VERSION "dbc-export 1 2025.20.8"

NS_ :

BS_:

BU_: APP APS DAS EPAS3S ESP GTW IBST PARK RADC RCM TPMS USM

BO_ 1045 APP_backupDashCamStatus: 1 APP
 SG_ APP_backupDashCamFeedGood : 0|1@1+ (1,0) [0|1] "" Vector__XXX
 SG_ APP_backupDashCamFrameRate : 1|7@1+ (1,0) [0|127] "" Vector__XXX

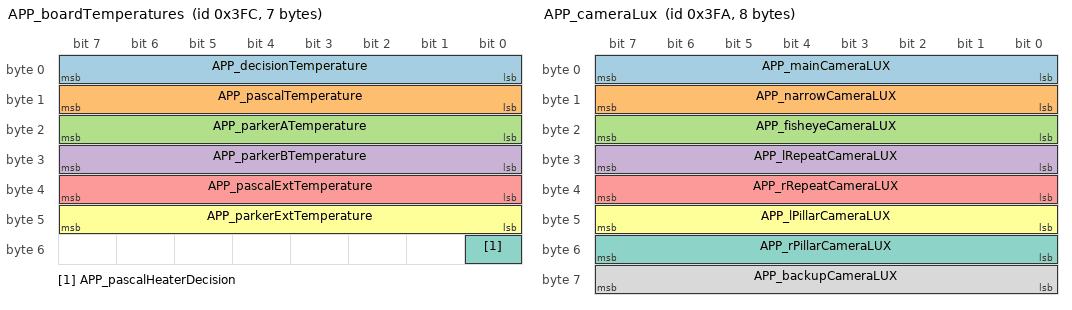
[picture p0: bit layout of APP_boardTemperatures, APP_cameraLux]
BO_ 1020 APP_boardTemperatures: 7 APP
 SG_ APP_decisionTemperature : 0|8@1+ (1,-128) [-128|127] "C" Vector__XXX
 SG_ APP_pascalTemperature : 8|8@1+ (1,-128) [-128|127] "C" Vector__XXX
 SG_ APP_parkerATemperature : 16|8@1+ (1,-128) [-128|127] "C" Vector__XXX
 SG_ APP_parkerBTemperature : 24|8@1+ (1,-128) [-128|127] "C" Vector__XXX
 SG_ APP_pascalExtTemperature : 32|8@1+ (1,-128) [-128|127] "C" Vector__XXX
 SG_ APP_parkerExtTemperature : 40|8@1+ (1,-128) [-128|127] "C" Vector__XXX
 SG_ APP_pascalHeaterDecision : 48|1@1+ (1,0) [0|1] "" Vector__XXX

BO_ 1018 APP_cameraLux: 8 APP
 SG_ APP_mainCameraLUX : 0|8@1+ (0.5,0) [0|127] "lux^0.5" Vector__XXX
 SG_ APP_narrowCameraLUX : 8|8@1+ (0.5,0) [0|127] "lux^0.5" Vector__XXX
 SG_ APP_fisheyeCameraLUX : 16|8@1+ (0.5,0) [0|127] "lux^0.5" Vector__XXX
 SG_ APP_lRepeatCameraLUX : 24|8@1+ (0.5,0) [0|127] "lux^0.5" Vector__XXX
 SG_ APP_rRepeatCameraLUX : 32|8@1+ (0.5,0) [0|127] "lux^0.5" Vector__XXX
 SG_ APP_lPillarCameraLUX : 40|8@1+ (0.5,0) [0|127] "lux^0.5" Vector__XXX
 SG_ APP_rPillarCameraLUX : 48|8@1+ (0.5,0) [0|127] "lux^0.5" Vector__XXX
 SG_ APP_backupCameraLUX : 56|8@1+ (0.5,0) [0|127] "lux^0.5" Vector__XXX

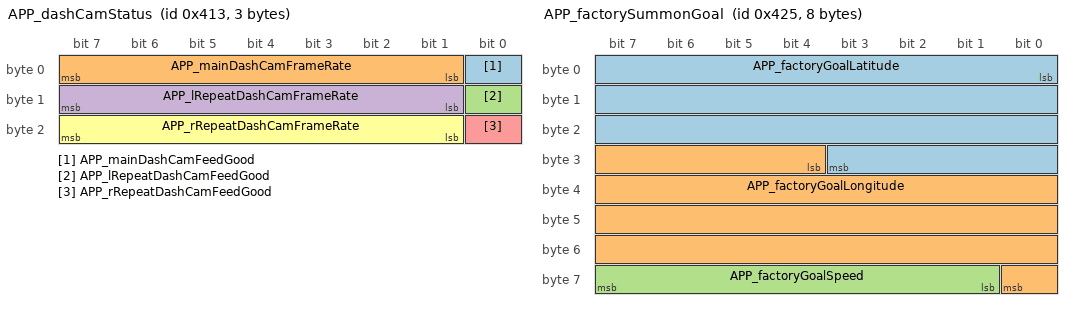
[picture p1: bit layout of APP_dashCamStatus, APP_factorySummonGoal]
BO_ 1043 APP_dashCamStatus: 3 APP
 SG_ APP_mainDashCamFeedGood : 0|1@1+ (1,0) [0|1] "" Vector__XXX
 SG_ APP_mainDashCamFrameRate : 1|7@1+ (1,0) [0|127] "" Vector__XXX
 SG_ APP_lRepeatDashCamFeedGood : 8|1@1+ (1,0) [0|1] "" Vector__XXX
 SG_ APP_lRepeatDashCamFrameRate : 9|7@1+ (1,0) [0|127] "" Vector__XXX
 SG_ APP_rRepeatDashCamFeedGood : 16|1@1+ (1,0) [0|1] "" Vector__XXX
 SG_ APP_rRepeatDashCamFrameRate : 17|7@1+ (1,0) [0|127] "" Vector__XXX

BO_ 1061 APP_factorySummonGoal: 8 APP
 SG_ APP_factoryGoalLatitude : 0|28@1- (1.0e-06,0) [-134.217728|134.217727] "deg" Vector__XXX
 SG_ APP_factoryGoalLongitude : 28|29@1- (1.0e-06,0) [-268.435456|268.435454] "deg" Vector__XXX
 SG_ APP_factoryGoalSpeed : 57|7@1+ (1,0) [0|100] "mph" Vector__XXX

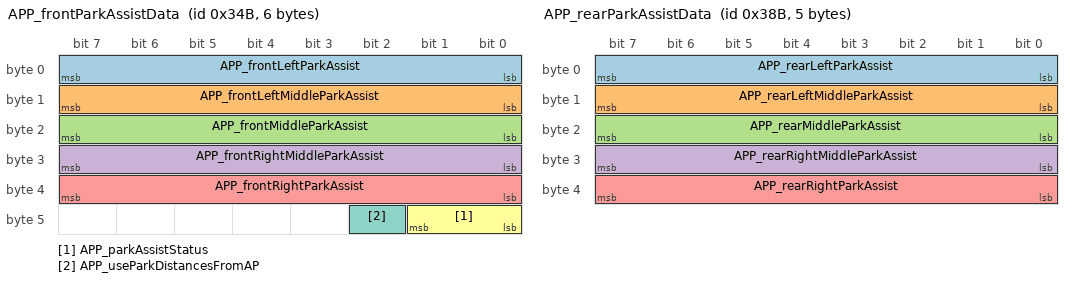
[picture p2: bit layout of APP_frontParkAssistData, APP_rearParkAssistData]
BO_ 843 APP_frontParkAssistData: 6 APP
 SG_ APP_frontLeftParkAssist : 0|8@1+ (1,0) [0|254] "cm" Vector__XXX
 SG_ APP_frontLeftMiddleParkAssist : 8|8@1+ (1,0) [0|254] "cm" Vector__XXX
 SG_ APP_frontMiddleParkAssist : 16|8@1+ (1,0) [0|254] "cm" Vector__XXX
 SG_ APP_frontRightMiddleParkAssist : 24|8@1+ (1,0) [0|254] "cm" Vector__XXX
 SG_ APP_frontRightParkAssist : 32|8@1+ (1,0) [0|254] "cm" Vector__XXX
 SG_ APP_parkAssistStatus : 40|2@1+ (1,0) [0|2] "" Vector__XXX
 SG_ APP_useParkDistancesFromAP : 42|1@1+ (1,0) [0|1] "" Vector__XXX

BO_ 1353 APP_info: 8 APP
 SG_ APP_infoIndex M : 0|8@1+ (1,0) [0|255] "" Vector__XXX
 SG_ APP_buildType m0 : 8|8@1+ (1,0) [0|255] "" Vector__XXX

BO_ 907 APP_rearParkAssistData: 5 APP
 SG_ APP_rearLeftParkAssist : 0|8@1+ (1,0) [0|254] "cm" Vector__XXX
 SG_ APP_rearLeftMiddleParkAssist : 8|8@1+ (1,0) [0|254] "cm" Vector__XXX
 SG_ APP_rearMiddleParkAssist : 16|8@1+ (1,0) [0|254] "cm" Vector__XXX
 SG_ APP_rearRightMiddleParkAssist : 24|8@1+ (1,0) [0|254] "cm" Vector__XXX
 SG_ APP_rearRightParkAssist : 32|8@1+ (1,0) [0|254] "cm" Vector__XXX

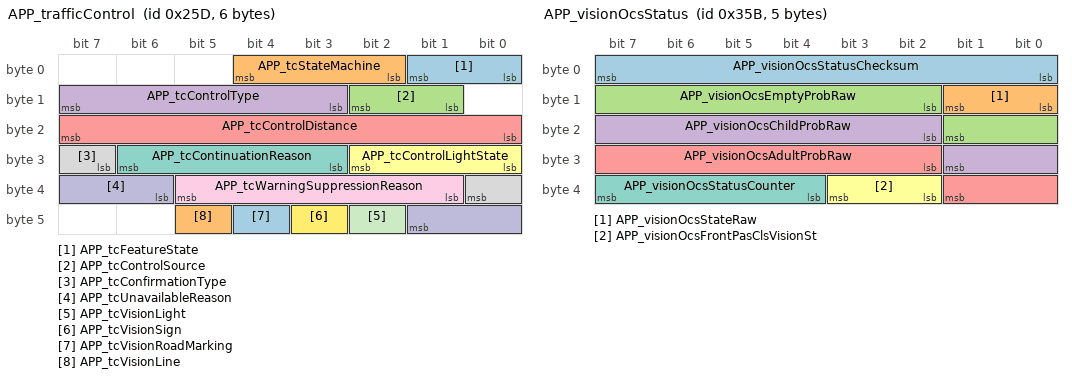
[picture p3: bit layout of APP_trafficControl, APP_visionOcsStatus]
BO_ 605 APP_trafficControl: 6 APP
 SG_ APP_tcFeatureState : 0|2@1+ (1,0) [0|3] "" Vector__XXX
 SG_ APP_tcStateMachine : 2|3@1+ (1,0) [0|7] "" Vector__XXX
 SG_ APP_tcControlSource : 9|2@1+ (1,0) [0|3] "" Vector__XXX
 SG_ APP_tcControlType : 11|5@1+ (1,0) [0|31] "" Vector__XXX
 SG_ APP_tcControlDistance : 16|8@1+ (1,0) [0|254] "m" Vector__XXX
 SG_ APP_tcControlLightState : 24|3@1+ (1,0) [0|7] "" Vector__XXX
 SG_ APP_tcContinuationReason : 27|4@1+ (1,0) [0|15] "" Vector__XXX
 SG_ APP_tcConfirmationType : 31|2@1+ (1,0) [0|3] "" Vector__XXX
 SG_ APP_tcWarningSuppressionReason : 33|5@1+ (1,0) [0|31] "" Vector__XXX
 SG_ APP_tcUnavailableReason : 38|4@1+ (1,0) [0|15] "" Vector__XXX
 SG_ APP_tcVisionLight : 42|1@1+ (1,0) [0|1] "" Vector__XXX
 SG_ APP_tcVisionSign : 43|1@1+ (1,0) [0|1] "" Vector__XXX
 SG_ APP_tcVisionRoadMarking : 44|1@1+ (1,0) [0|1] "" Vector__XXX
 SG_ APP_tcVisionLine : 45|1@1+ (1,0) [0|1] "" Vector__XXX

BO_ 859 APP_visionOcsStatus: 5 APP
 SG_ APP_visionOcsStatusChecksum : 0|8@1+ (1,0) [0|255] "" Vector__XXX
 SG_ APP_visionOcsStateRaw : 8|2@1+ (1,0) [0|3] "" Vector__XXX
 SG_ APP_visionOcsEmptyProbRaw : 10|8@1+ (0.004,0) [0|1.016] "points" Vector__XXX
 SG_ APP_visionOcsChildProbRaw : 18|8@1+ (0.004,0) [0|1.016] "points" Vector__XXX
 SG_ APP_visionOcsAdultProbRaw : 26|8@1+ (0.004,0) [0|1.016] "points" Vector__XXX
 SG_ APP_visionOcsFrontPasClsVisionSt : 34|2@1+ (1,0) [0|3] "" Vector__XXX
 SG_ APP_visionOcsStatusCounter : 36|4@1+ (1,0) [0|15] "" Vector__XXX

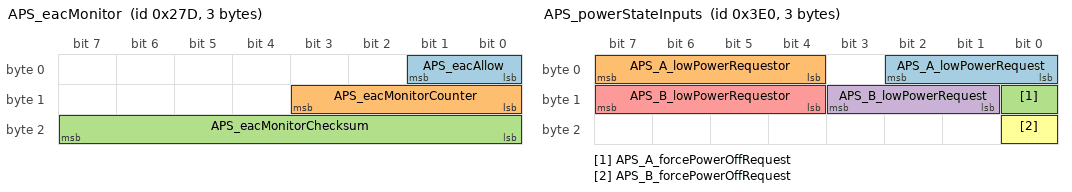
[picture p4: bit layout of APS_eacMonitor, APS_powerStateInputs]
BO_ 637 APS_eacMonitor: 3 APS
 SG_ APS_eacAllow : 0|2@1+ (1,0) [0|2] "" Vector__XXX
 SG_ APS_eacMonitorCounter : 8|4@1+ (1,0) [0|15] "" Vector__XXX
 SG_ APS_eacMonitorChecksum : 16|8@1+ (1,0) [0|255] "" Vector__XXX

BO_ 992 APS_powerStateInputs: 3 APS
 SG_ APS_A_lowPowerRequest : 0|3@1+ (1,0) [0|7] "" Vector__XXX
 SG_ APS_A_lowPowerRequestor : 4|4@1+ (1,0) [0|15] "" Vector__XXX
 SG_ APS_A_forcePowerOffRequest : 8|1@1+ (1,0) [0|1] "" Vector__XXX
 SG_ APS_B_lowPowerRequest : 9|3@1+ (1,0) [0|7] "" Vector__XXX
 SG_ APS_B_lowPowerRequestor : 12|4@1+ (1,0) [0|15] "" Vector__XXX
 SG_ APS_B_forcePowerOffRequest : 16|1@1+ (1,0) [0|1] "" Vector__XXX

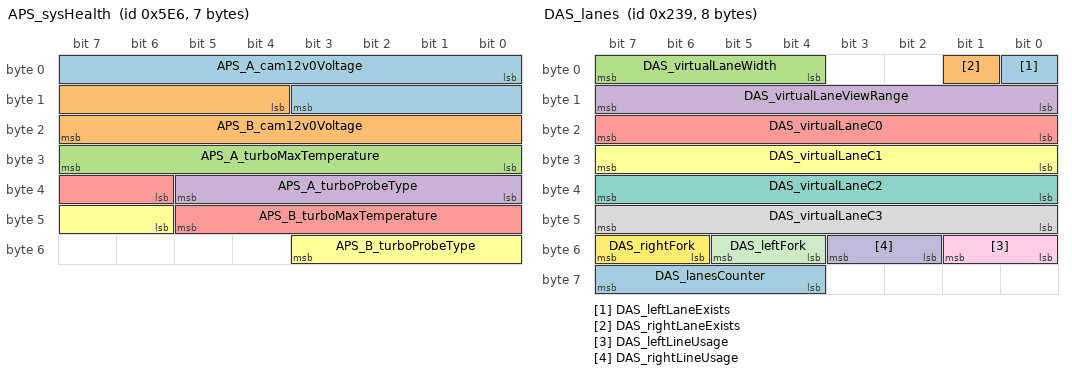
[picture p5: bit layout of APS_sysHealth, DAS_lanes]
BO_ 1510 APS_sysHealth: 7 APS
 SG_ APS_A_cam12v0Voltage : 0|12@1+ (0.0048,0) [0|19.44] "V" Vector__XXX
 SG_ APS_B_cam12v0Voltage : 12|12@1+ (0.0048,0) [0|19.44] "V" Vector__XXX
 SG_ APS_A_turboMaxTemperature : 24|8@1- (1,0) [-128|127] "degC" Vector__XXX
 SG_ APS_A_turboProbeType : 32|6@1+ (1,0) [0|62] "" Vector__XXX
 SG_ APS_B_turboMaxTemperature : 38|8@1- (1,0) [-128|127] "degC" Vector__XXX
 SG_ APS_B_turboProbeType : 46|6@1+ (1,0) [0|62] "" Vector__XXX

BO_ 1497 DAS_carLog: 8 DAS
 SG_ DAS_carLogMultiplexer M : 0|4@1+ (1,0) [0|15] "" Vector__XXX
 SG_ DAS_radarTarget5_dx m1 : 4|12@1+ (0.0625,0) [0|255.9375] "m" Vector__XXX
 SG_ DAS_radarTarget1_dx m1 : 24|12@1+ (0.0625,0) [0|255.9375] "m" Vector__XXX
 SG_ DAS_radarTarget1_VxRel m1 : 36|8@1+ (0.2,-25.6) [-25.6|25.4] "m/s" Vector__XXX
 SG_ DAS_mobileyeVehAebFlag m2 : 4|1@1+ (1,0) [0|1] "" Vector__XXX
 SG_ DAS_mobileyePedAebFlag m2 : 5|1@1+ (1,0) [0|1] "" Vector__XXX
 SG_ DAS_mobileyeIPSOapproved m2 : 6|1@1+ (1,0) [0|1] "" Vector__XXX
 SG_ DAS_fcmSteeringOverride m2 : 7|1@1+ (1,0) [0|1] "" Vector__XXX
 SG_ DAS_fcmCollisionStage3Checks m2 : 8|8@1+ (1,0) [0|255] "" Vector__XXX
 SG_ DAS_fcmThreatAssesmentMode m2 : 16|3@1+ (1,0) [0|7] "" Vector__XXX
 SG_ DAS_constructionArea m2 : 19|2@1+ (1,0) [0|3] "" Vector__XXX
 SG_ DAS_restrictionLowSpeedTraffic m2 : 21|1@1+ (1,0) [0|1] "" Vector__XXX
 SG_ DAS_associated_rad_object m2 : 22|2@1+ (1,0) [0|3] "" Vector__XXX
 SG_ DAS_LC_handsOnReason m2 : 24|6@1+ (1,0) [0|63] "" Vector__XXX
 SG_ DAS_ACC_camStatus m2 : 30|2@1+ (1,0) [0|3] "" Vector__XXX
 SG_ DAS_aeb_not_activating_reason m2 : 32|5@1+ (1,0) [0|31] "" Vector__XXX
 SG_ DAS_handsOnDetected m2 : 38|2@1+ (1,0) [1|3] "" Vector__XXX
 SG_ DAS_driveOnNavUnavailableReason m2 : 40|5@1+ (1,0) [0|31] "" Vector__XXX
 SG_ DAS_accUnavailableReason m2 : 46|7@1+ (1,0) [0|127] "" Vector__XXX
 SG_ DAS_pmmNotActivatingReason m2 : 53|5@1+ (1,0) [0|31] "" Vector__XXX
 SG_ DAS_desiredTarget_dx m3 : 16|8@1+ (0.5,0) [0|127] "m" Vector__XXX
 SG_ DAS_radarTarget2_dx m3 : 24|12@1+ (0.0625,0) [0|255.9375] "m" Vector__XXX
 SG_ DAS_radarTarget3_dx m3 : 36|12@1+ (0.0625,0) [0|255.9375] "m" Vector__XXX
 SG_ DAS_radarTarget4_dx m3 : 48|12@1+ (0.0625,0) [0|255.9375] "m" Vector__XXX
 SG_ DAS_closestInLaneTargetDx m4 : 4|12@1+ (0.0625,0) [0|255.9375] "m" Vector__XXX
 SG_ DAS_secondInLaneTargetDx m4 : 16|12@1+ (0.0625,0) [0|255.9375] "m" Vector__XXX
 SG_ DAS_closestLeftLaneTargetDx m4 : 28|12@1+ (0.0625,0) [0|255.9375] "m" Vector__XXX
 SG_ DAS_closestRightLaneTargetDx m4 : 40|12@1+ (0.0625,0) [0|255.9375] "m" Vector__XXX
 SG_ DAS_closestInLaneTargetVxRel m4 : 52|10@1+ (0.1,-51.1) [-51.1|51.2] "m/s" Vector__XXX

BO_ 1337 DAS_info: 8 DAS
 SG_ DAS_infoIndex M : 0|8@1+ (1,0) [0|255] "" Vector__XXX
 SG_ DAS_infoBuildType m10 : 8|8@1+ (1,0) [0|255] "" Vector__XXX
 SG_ DAS_infoBuildConfigID m10 : 16|16@1+ (1,0) [0|65535] "" Vector__XXX
 SG_ DAS_infoHardwareID m10 : 32|16@1+ (1,0) [0|65535] "" Vector__XXX
 SG_ DAS_infoComponentID m10 : 48|16@1+ (1,0) [0|65535] "" Vector__XXX
 SG_ DAS_infoPcbaID m11 : 16|8@1+ (1,0) [0|255] "" Vector__XXX
 SG_ DAS_infoAssemblyID m11 : 24|8@1+ (1,0) [0|255] "" Vector__XXX
 SG_ DAS_infoUsageID m11 : 32|16@1+ (1,0) [0|65535] "" Vector__XXX
 SG_ DAS_infoSubUsageID m11 : 48|16@1+ (1,0) [0|65535] "" Vector__XXX
 SG_ DAS_infoApplicationCRC m13 : 32|32@1+ (1,0) [0|4294967295] "" Vector__XXX
 SG_ DAS_infoAppGitHashBytes m17 : 8|56@1+ (1,0) [0|7.20575940379e+16] "" Vector__XXX
 SG_ DAS_infoBootGitHashBytes m18 : 8|56@1+ (1,0) [0|7.20575940379e+16] "" Vector__XXX

BO_ 569 DAS_lanes: 8 DAS
 SG_ DAS_leftLaneExists : 0|1@1+ (1,0) [0|1] "" Vector__XXX
 SG_ DAS_rightLaneExists : 1|1@1+ (1,0) [0|1] "" Vector__XXX
 SG_ DAS_virtualLaneWidth : 4|4@1+ (0.3125,2) [2|6.6875] "m" Vector__XXX
 SG_ DAS_virtualLaneViewRange : 8|8@1+ (1,0) [0|160] "m" Vector__XXX
 SG_ DAS_virtualLaneC0 : 16|8@1+ (0.035,-3.5) [-3.5|3.5] "m" Vector__XXX
 SG_ DAS_virtualLaneC1 : 24|8@1+ (0.0016,-0.2) [-0.2|0.2] "rad" Vector__XXX
 SG_ DAS_virtualLaneC2 : 32|8@1+ (2.0e-05,-0.0025) [-0.0025|0.0025] "m-1" Vector__XXX
 SG_ DAS_virtualLaneC3 : 40|8@1+ (2.4e-07,-3.0e-05) [-3.0e-05|3.0e-05] "m-2" Vector__XXX
 SG_ DAS_leftLineUsage : 48|2@1+ (1,0) [0|3] "" Vector__XXX
 SG_ DAS_rightLineUsage : 50|2@1+ (1,0) [0|3] "" Vector__XXX
 SG_ DAS_leftFork : 52|2@1+ (1,0) [0|3] "" Vector__XXX
 SG_ DAS_rightFork : 54|2@1+ (1,0) [0|3] "" Vector__XXX
 SG_ DAS_lanesCounter : 60|4@1+ (1,0) [0|15] "" Vector__XXX

BO_ 921 DAS_status: 8 DAS
 SG_ DAS_autopilotState : 0|4@1+ (1,0) [0|14] "" Vector__XXX
 SG_ DAS_blindSpotRearLeft : 4|2@1+ (1,0) [0|2] "" Vector__XXX
 SG_ DAS_blindSpotRearRight : 6|2@1+ (1,0) [0|2] "" Vector__XXX
 SG_ DAS_fusedSpeedLimit : 8|5@1+ (5,0) [5|150] "kph/mph" Vector__XXX
 SG_ DAS_suppressSpeedWarning : 13|1@1+ (1,0) [0|1] "" Vector__XXX
 SG_ DAS_summonObstacle : 14|1@1+ (1,0) [0|1] "" Vector__XXX
 SG_ DAS_summonClearedGate : 15|1@1+ (1,0) [0|1] "" Vector__XXX
 SG_ DAS_visionOnlySpeedLimit : 16|5@1+ (5,0) [5|150] "kph/mph" Vector__XXX
 SG_ DAS_heaterState : 21|1@1+ (1,0) [0|1] "" Vector__XXX
 SG_ DAS_forwardCollisionWarning : 22|2@1+ (1,0) [0|2] "" Vector__XXX
 SG_ DAS_autoparkReady : 24|1@1+ (1,0) [0|1] "" Vector__XXX
 SG_ DAS_autoParked : 25|1@1+ (1,0) [0|1] "" Vector__XXX
 SG_ DAS_autoparkActive : 26|1@1+ (1,0) [0|1] "" Vector__XXX
 SG_ DAS_summonFwdLeashReached : 27|1@1+ (1,0) [0|1] "" Vector__XXX
 SG_ DAS_summonRvsLeashReached : 28|1@1+ (1,0) [0|1] "" Vector__XXX
 SG_ DAS_lssState : 29|3@1+ (1,0) [0|7] "" Vector__XXX
 SG_ DAS_sideCollisionAvoid : 32|2@1+ (1,0) [0|2] "" Vector__XXX
 SG_ DAS_sideCollisionWarning : 34|2@1+ (1,0) [0|3] "" Vector__XXX
 SG_ DAS_sideCollisionInhibit : 36|1@1+ (1,0) [0|1] "" Vector__XXX
 SG_ DAS_laneDepartureWarning : 37|3@1+ (1,0) [0|7] "" Vector__XXX
 SG_ DAS_fleetSpeedState : 40|2@1+ (1,0) [0|3] "" Vector__XXX
 SG_ DAS_autopilotHandsOnState : 42|4@1+ (1,0) [0|14] "" Vector__XXX
 SG_ DAS_autoLaneChangeState : 46|5@1+ (1,0) [0|30] "" Vector__XXX
 SG_ DAS_summonAvailable : 51|1@1+ (1,0) [0|1] "" Vector__XXX
 SG_ DAS_statusCounter : 52|4@1+ (1,0) [0|15] "" Vector__XXX
 SG_ DAS_statusChecksum : 56|8@1+ (1,0) [0|255] "" Vector__XXX

BO_ 905 DAS_status2: 8 DAS
 SG_ DAS_accSpeedLimit : 0|9@1+ (0.4,0) [0|200] "mph" Vector__XXX
 SG_ DAS_versionIdentifier : 9|1@1+ (1,0) [0|1] "" Vector__XXX
 SG_ DAS_pmmObstacleSeverity : 10|3@1+ (1,0) [0|6] "" Vector__XXX
 SG_ DAS_pmmLoggingRequest : 13|1@1+ (1,0) [0|1] "" Vector__XXX
 SG_ DAS_activationFailureStatus : 14|2@1+ (1,0) [0|3] "" Vector__XXX
 SG_ DAS_pmmUltrasonicsFaultReason : 16|3@1+ (1,0) [0|7] "" Vector__XXX
 SG_ DAS_pmmRadarFaultReason : 19|2@1+ (1,0) [0|3] "" Vector__XXX
 SG_ DAS_pmmSysFaultReason : 21|3@1+ (1,0) [0|7] "" Vector__XXX
 SG_ DAS_pmmCameraFaultReason : 24|2@1+ (1,0) [0|3] "" Vector__XXX
 SG_ DAS_ACC_report : 26|5@1+ (1,0) [0|31] "" Vector__XXX
 SG_ DAS_relaxCruiseLimits : 31|1@1+ (1,0) [0|1] "" Vector__XXX
 SG_ DAS_csaState : 32|2@1+ (1,0) [0|3] "" Vector__XXX
 SG_ DAS_radarTelemetry : 34|2@1+ (1,0) [0|3] "" Vector__XXX
 SG_ DAS_robState : 36|2@1+ (1,0) [0|3] "" Vector__XXX
 SG_ DAS_driverInteractionLevel : 38|2@1+ (1,0) [0|3] "" Vector__XXX
 SG_ DAS_ppOffsetDesiredRamp : 40|8@1+ (0.01,-1.28) [-1.28|1.27] "m" Vector__XXX
 SG_ DAS_longCollisionWarning : 48|4@1+ (1,0) [0|14] "" Vector__XXX
 SG_ DAS_status2Counter : 52|4@1+ (1,0) [0|15] "" Vector__XXX
 SG_ DAS_status2Checksum : 56|8@1+ (1,0) [0|255] "" Vector__XXX

BO_ 586 DAS_visualDebug: 8 DAS
 SG_ DAS_autosteerVehiclesUsage : 4|2@1+ (1,0) [0|3] "" Vector__XXX
 SG_ DAS_autosteerHPPUsage : 6|2@1+ (1,0) [0|3] "" Vector__XXX
 SG_ DAS_autosteerNavigationUsage : 8|2@1+ (1,0) [0|3] "" Vector__XXX
 SG_ DAS_autosteerModelUsage : 10|2@1+ (1,0) [0|3] "" Vector__XXX
 SG_ DAS_autosteerBottsDotsUsage : 12|2@1+ (1,0) [0|3] "" Vector__XXX
 SG_ DAS_offsetSide : 14|2@1+ (1,0) [0|3] "" Vector__XXX
 SG_ DAS_roadSurfaceType : 16|2@1+ (1,0) [1|3] "" Vector__XXX
 SG_ DAS_autosteerHealthAnomalyLevel : 18|3@1+ (1,0) [0|7] "" Vector__XXX
 SG_ DAS_autosteerHealthState : 21|3@1+ (1,0) [0|7] "" Vector__XXX
 SG_ DAS_lastLinePreferenceReason : 24|4@1+ (1,0) [0|15] "" Vector__XXX
 SG_ DAS_plannerState : 28|4@1+ (1,0) [0|15] "" Vector__XXX
 SG_ DAS_lastAutosteerAbortReason : 32|6@1+ (1,0) [0|63] "" Vector__XXX
 SG_ DAS_devAppInterfaceEnabled : 38|1@1+ (1,0) [0|1] "" Vector__XXX
 SG_ DAS_navAvailable : 39|1@1+ (1,0) [0|1] "" Vector__XXX
 SG_ DAS_navDistance : 40|8@1+ (100,0) [0|25500] "km" Vector__XXX
 SG_ DAS_accSmartSpeedActive : 48|1@1+ (1,0) [0|1] "" Vector__XXX
 SG_ DAS_accSmartSpeedState : 49|3@1+ (1,0) [0|6] "" Vector__XXX
 SG_ DAS_ulcInProgress : 52|1@1+ (1,0) [0|1] "" Vector__XXX
 SG_ DAS_trafficAwareSetSpeedInUse : 53|1@1+ (1,0) [0|1] "" Vector__XXX
 SG_ DAS_isaSystemState : 54|2@1+ (1,0) [0|3] "" Vector__XXX
 SG_ DAS_behaviorType : 56|2@1+ (1,0) [0|3] "" Vector__XXX
 SG_ DAS_ulcType : 58|2@1+ (1,0) [0|3] "" Vector__XXX
 SG_ DAS_rearVehDetectedThisCycle : 60|1@1+ (1,0) [0|1] "" Vector__XXX
 SG_ DAS_rearLeftVehDetectedCurrent : 61|1@1+ (1,0) [0|1] "" Vector__XXX
 SG_ DAS_rearRightVehDetectedTrip : 62|1@1+ (1,0) [0|1] "" Vector__XXX
 SG_ DAS_rearLeftVehDetectedTrip : 63|1@1+ (1,0) [0|1] "" Vector__XXX

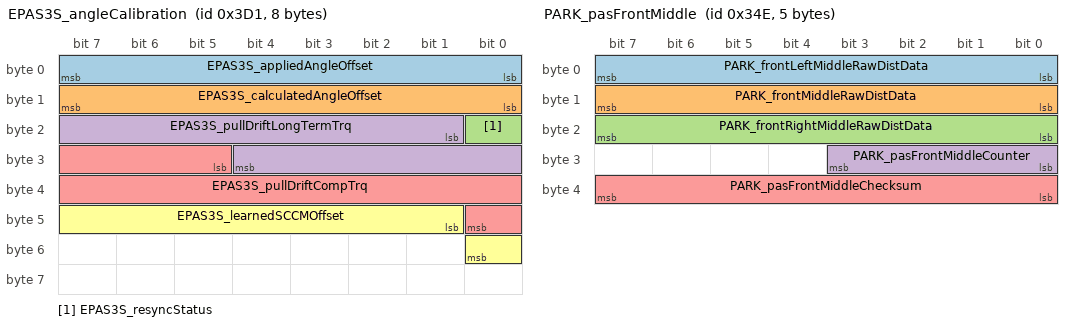
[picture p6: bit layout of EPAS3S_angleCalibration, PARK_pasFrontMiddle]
BO_ 977 EPAS3S_angleCalibration: 8 EPAS3S
 SG_ EPAS3S_appliedAngleOffset : 0|8@1+ (0.1,-12.8) [-12.8|12.7] "deg" Vector__XXX
 SG_ EPAS3S_calculatedAngleOffset : 8|8@1+ (0.1,-12.8) [-12.8|12.7] "deg" Vector__XXX
 SG_ EPAS3S_resyncStatus : 16|1@1+ (1,0) [0|1] "" Vector__XXX
 SG_ EPAS3S_pullDriftLongTermTrq : 17|12@1+ (0.01,-10) [-10|10] "Nm" Vector__XXX
 SG_ EPAS3S_pullDriftCompTrq : 29|12@1+ (0.01,-10) [-10|10] "Nm" Vector__XXX
 SG_ EPAS3S_learnedSCCMOffset : 41|8@1+ (0.1,-12.8) [-12.8|12.7] "deg" Vector__XXX

BO_ 785 EPAS3S_info: 8 EPAS3S
 SG_ EPAS3S_infoIndex M : 0|8@1+ (1,0) [0|255] "" Vector__XXX
 SG_ EPAS3S_infoBuildType m10 : 8|8@1+ (1,0) [0|255] "" Vector__XXX
 SG_ EPAS3S_infoComponentID m10 : 48|16@1+ (1,0) [0|65535] "" Vector__XXX
 SG_ EPAS3S_infoPcbaID m11 : 16|8@1+ (1,0) [0|255] "" Vector__XXX
 SG_ EPAS3S_infoAssemblyID m11 : 24|8@1+ (1,0) [0|255] "" Vector__XXX
 SG_ EPAS3S_infoUsageID m11 : 32|16@1+ (1,0) [0|65535] "" Vector__XXX
 SG_ EPAS3S_infoApplicationCRC m13 : 32|32@1+ (1,0) [0|4294967295] "" Vector__XXX
 SG_ EPAS3S_infoBootUdsProtoVersion m20 : 8|8@1+ (1,0) [0|255] "" Vector__XXX
 SG_ EPAS3S_infoBootloaderCRC m20 : 32|32@1+ (1,0) [0|4294967295] "" Vector__XXX
 SG_ EPAS3S_infoSubcomponent2 m23 : 32|32@1+ (1,0) [0|4294967295] "" Vector__XXX

BO_ 805 ESP_info: 8 ESP
 SG_ ESP_infoIndex M : 0|8@1+ (1,0) [0|255] "" Vector__XXX
 SG_ ESP_infoBuildType m10 : 8|8@1+ (1,0) [0|255] "" Vector__XXX
 SG_ ESP_infoComponentID m10 : 48|16@1+ (1,0) [0|65535] "" Vector__XXX
 SG_ ESP_infoPcbaID m11 : 16|8@1+ (1,0) [0|255] "" Vector__XXX
 SG_ ESP_infoAssemblyID m11 : 24|8@1+ (1,0) [0|255] "" Vector__XXX
 SG_ ESP_infoUsageID m11 : 32|16@1+ (1,0) [0|65535] "" Vector__XXX
 SG_ ESP_infoSubUsageID m11 : 48|16@1+ (1,0) [0|65535] "" Vector__XXX
 SG_ ESP_infoApplicationCRC m13 : 39|32@0+ (1,0) [0|4294967295] "" Vector__XXX
 SG_ ESP_infoVehicleVariant m16 : 16|8@1+ (1,0) [0|255] "" Vector__XXX
 SG_ ESP_infoSubcomponent1 m16 : 32|32@1+ (1,0) [0|4294967295] "" Vector__XXX
 SG_ ESP_infoBootUdsProtoVersion m20 : 8|8@1+ (1,0) [0|255] "" Vector__XXX
 SG_ ESP_infoBootloaderCRC m20 : 32|32@1+ (1,0) [0|4294967295] "" Vector__XXX
 SG_ ESP_infoVariantCRC m22 : 39|32@0+ (1,0) [0|4294967295] "" Vector__XXX

BO_ 813 IBST_info: 8 IBST
 SG_ IBST_infoIndex M : 0|8@1+ (1,0) [0|255] "" Vector__XXX
 SG_ IBST_infoBuildType m10 : 8|8@1+ (1,0) [0|255] "" Vector__XXX
 SG_ IBST_infoComponentID m10 : 55|16@0+ (1,0) [0|65535] "" Vector__XXX
 SG_ IBST_infoPcbaID m11 : 16|8@1+ (1,0) [0|255] "" Vector__XXX
 SG_ IBST_infoAssemblyID m11 : 24|8@1+ (1,0) [0|255] "" Vector__XXX
 SG_ IBST_infoUsageID m11 : 32|16@1+ (1,0) [0|65535] "" Vector__XXX
 SG_ IBST_infoSubUsageID m11 : 48|16@1+ (1,0) [0|65535] "" Vector__XXX
 SG_ IBST_infoApplicationCRC m13 : 32|32@1+ (1,0) [0|4294967295] "" Vector__XXX
 SG_ IBST_infoBootUdsProtoVersion m20 : 8|8@1+ (1,0) [0|255] "" Vector__XXX
 SG_ IBST_infoBootloaderCRC m20 : 32|32@1+ (1,0) [0|4294967295] "" Vector__XXX
 SG_ IBST_infoVariantCRC m22 : 32|32@1+ (1,0) [0|4294967295] "" Vector__XXX

BO_ 806 PARK_info: 8 PARK
 SG_ PARK_infoIndex M : 0|8@1+ (1,0) [0|255] "" Vector__XXX
 SG_ PARK_infoBuildType m10 : 8|8@1+ (1,0) [0|255] "" Vector__XXX
 SG_ PARK_infoComponentID m10 : 48|16@1+ (1,0) [0|65535] "" Vector__XXX
 SG_ PARK_infoPcbaID m11 : 16|8@1+ (1,0) [0|255] "" Vector__XXX
 SG_ PARK_infoAssemblyID m11 : 24|8@1+ (1,0) [0|255] "" Vector__XXX
 SG_ PARK_infoUsageID m11 : 32|16@1+ (1,0) [0|65535] "" Vector__XXX
 SG_ PARK_infoApplicationCRC m13 : 32|32@1+ (1,0) [0|4294967295] "" Vector__XXX
 SG_ PARK_infoBootUdsProtoVersion m20 : 8|8@1+ (1,0) [0|255] "" Vector__XXX
 SG_ PARK_infoBootloaderCRC m20 : 32|32@1+ (1,0) [0|4294967295] "" Vector__XXX

BO_ 846 PARK_pasFrontMiddle: 5 PARK
 SG_ PARK_frontLeftMiddleRawDistData : 0|8@1+ (1,0) [0|254] "cm" Vector__XXX
 SG_ PARK_frontMiddleRawDistData : 8|8@1+ (1,0) [0|254] "cm" Vector__XXX
 SG_ PARK_frontRightMiddleRawDistData : 16|8@1+ (1,0) [0|254] "cm" Vector__XXX
 SG_ PARK_pasFrontMiddleCounter : 24|4@1+ (1,0) [0|15] "" Vector__XXX
 SG_ PARK_pasFrontMiddleChecksum : 32|8@1+ (1,0) [0|255] "" Vector__XXX

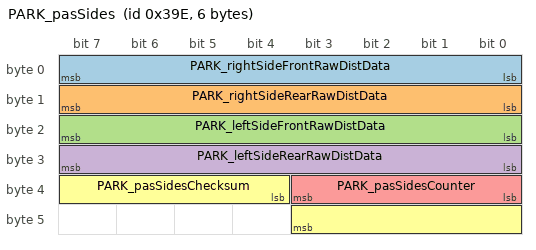
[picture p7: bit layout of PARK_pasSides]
BO_ 926 PARK_pasSides: 6 PARK
 SG_ PARK_rightSideFrontRawDistData : 0|8@1+ (1,0) [0|254] "cm" Vector__XXX
 SG_ PARK_rightSideRearRawDistData : 8|8@1+ (1,0) [0|254] "cm" Vector__XXX
 SG_ PARK_leftSideFrontRawDistData : 16|8@1+ (1,0) [0|254] "cm" Vector__XXX
 SG_ PARK_leftSideRearRawDistData : 24|8@1+ (1,0) [0|254] "cm" Vector__XXX
 SG_ PARK_pasSidesCounter : 32|4@1+ (1,0) [0|15] "" Vector__XXX
 SG_ PARK_pasSidesChecksum : 36|8@1+ (1,0) [0|255] "" Vector__XXX

BO_TX_BU_ 1045 : APP;
BO_TX_BU_ 1020 : APP;
BO_TX_BU_ 1018 : APP;
BO_TX_BU_ 1043 : APP;
BO_TX_BU_ 1061 : APP;
BO_TX_BU_ 843 : APP;
BO_TX_BU_ 1353 : APP;
BO_TX_BU_ 907 : APP;
BO_TX_BU_ 605 : APP;
BO_TX_BU_ 859 : APP;
BO_TX_BU_ 637 : APS;
BO_TX_BU_ 992 : APS;
BO_TX_BU_ 1510 : APS;
BO_TX_BU_ 1497 : DAS;
BO_TX_BU_ 1337 : DAS;
BO_TX_BU_ 569 : DAS;
BO_TX_BU_ 921 : DAS;
BO_TX_BU_ 905 : DAS;
BO_TX_BU_ 586 : DAS;
BO_TX_BU_ 977 : EPAS3S;
BO_TX_BU_ 785 : EPAS3S;
BO_TX_BU_ 805 : ESP;
BO_TX_BU_ 813 : IBST;
BO_TX_BU_ 806 : PARK;
BO_TX_BU_ 846 : PARK;
BO_TX_BU_ 926 : PARK;

CM_ "Tesla Model 3 CAN bus database; bus CH (chassis CAN); firmware 2025.20.8. Decoded CAN signal definitions (layout, scaling, units, value tables).";
CM_ BU_ APP "Driver assistance computer (primary)";
CM_ BU_ APS "Driver assistance computer (secondary)";
CM_ BU_ DAS "Driver assistance computer";
CM_ BU_ EPAS3S "Electric power steering (secondary)";
CM_ BU_ ESP "Electronic stability control";
CM_ BU_ GTW "Gateway";
CM_ BU_ IBST "Electric brake booster";
CM_ BU_ PARK "Parking assist sensors";
CM_ BU_ RADC "Radar";
CM_ BU_ RCM "Restraint control module";
CM_ BU_ TPMS "Tire pressure monitoring";
CM_ BU_ USM "USM ECU";
CM_ BO_ 1045 "Driver assistance computer (primary) message: backup dash cam status";
CM_ SG_ 1045 APP_backupDashCamFeedGood "Indicates if the backup dash cam stream is healthy.";
CM_ SG_ 1045 APP_backupDashCamFrameRate "The backup dash cam frame rate.";
CM_ BO_ 1020 "Driver assistance computer (primary) message: board temperatures";
CM_ SG_ 1020 APP_decisionTemperature "Rolling average of Parker and Pascal temperature.";
CM_ SG_ 1020 APP_pascalTemperature "Temperature of Autopilot GPU";
CM_ SG_ 1020 APP_parkerATemperature "Temperature of Autopilot CPU(1)";
CM_ SG_ 1020 APP_parkerBTemperature "Temperature of Autopilot CPU(1)";
CM_ SG_ 1020 APP_pascalExtTemperature "External temperature of Autopilot GPU";
CM_ SG_ 1020 APP_parkerExtTemperature "External temperature of Parker";
CM_ SG_ 1020 APP_pascalHeaterDecision "Pascal heater descision on/off";
CM_ BO_ 1018 "Driver assistance computer (primary) message: camera lux";
CM_ SG_ 1018 APP_mainCameraLUX "Amount of illuminance seen by the main camera; raw 255 = signal not available (SNA)";
CM_ SG_ 1018 APP_narrowCameraLUX "Driver assistance computer (primary): narrow camera LUX; raw 255 = signal not available (SNA)";
CM_ SG_ 1018 APP_fisheyeCameraLUX "Driver assistance computer (primary): fisheye camera LUX; raw 255 = signal not available (SNA)";
CM_ SG_ 1018 APP_lRepeatCameraLUX "Driver assistance computer (primary): l repeat camera LUX; raw 255 = signal not available (SNA)";
CM_ SG_ 1018 APP_rRepeatCameraLUX "Driver assistance computer (primary): r repeat camera LUX; raw 255 = signal not available (SNA)";
CM_ SG_ 1018 APP_lPillarCameraLUX "Driver assistance computer (primary): l pillar camera LUX; raw 255 = signal not available (SNA)";
CM_ SG_ 1018 APP_rPillarCameraLUX "Driver assistance computer (primary): r pillar camera LUX; raw 255 = signal not available (SNA)";
CM_ SG_ 1018 APP_backupCameraLUX "Driver assistance computer (primary): backup camera LUX; raw 255 = signal not available (SNA)";
CM_ BO_ 1043 "Driver assistance computer (primary) message: dash cam status";
CM_ SG_ 1043 APP_mainDashCamFeedGood "Indicates if the main dash cam stream is healthy.";
CM_ SG_ 1043 APP_mainDashCamFrameRate "The main dash cam frame rate.";
CM_ SG_ 1043 APP_lRepeatDashCamFeedGood "Indicates if the left repeater dash cam stream is healthy.";
CM_ SG_ 1043 APP_lRepeatDashCamFrameRate "The left repeater dash cam frame rate.";
CM_ SG_ 1043 APP_rRepeatDashCamFeedGood "Indicates if the right repeater dash cam stream is healthy.";
CM_ SG_ 1043 APP_rRepeatDashCamFrameRate "The right repeater dash cam frame rate.";
CM_ BO_ 1061 "Driver assistance computer (primary) message: factory summon goal";
CM_ SG_ 1061 APP_factoryGoalLatitude "Driver assistance computer (primary): factory goal latitude";
CM_ SG_ 1061 APP_factoryGoalLongitude "Driver assistance computer (primary): factory goal longitude";
CM_ SG_ 1061 APP_factoryGoalSpeed "Driver assistance computer (primary): factory goal speed";
CM_ BO_ 843 "Driver assistance computer (primary) message: front park assist data";
CM_ SG_ 843 APP_frontLeftParkAssist "Driver assistance computer (primary): front left park assist; raw 255 = signal not available (SNA)";
CM_ SG_ 843 APP_frontLeftMiddleParkAssist "Driver assistance computer (primary): front left middle park assist; raw 255 = signal not available (SNA)";
CM_ SG_ 843 APP_frontMiddleParkAssist "Driver assistance computer (primary): front middle park assist; raw 255 = signal not available (SNA)";
CM_ SG_ 843 APP_frontRightMiddleParkAssist "Driver assistance computer (primary): front right middle park assist; raw 255 = signal not available (SNA)";
CM_ SG_ 843 APP_frontRightParkAssist "Driver assistance computer (primary): front right park assist; raw 255 = signal not available (SNA)";
CM_ SG_ 843 APP_parkAssistStatus "Driver assistance computer (primary): park assist status; raw 3 = signal not available (SNA)";
CM_ SG_ 843 APP_useParkDistancesFromAP "Driver assistance computer (primary): use park distances from AP";
CM_ BO_ 1353 "Driver assistance computer (primary) message: info";
CM_ SG_ 1353 APP_infoIndex "Driver assistance computer (primary): info index";
CM_ SG_ 1353 APP_buildType "Driver assistance computer (primary): build type";
CM_ BO_ 907 "Driver assistance computer (primary) message: rear park assist data";
CM_ SG_ 907 APP_rearLeftParkAssist "Driver assistance computer (primary): rear left park assist; raw 255 = signal not available (SNA)";
CM_ SG_ 907 APP_rearLeftMiddleParkAssist "Driver assistance computer (primary): rear left middle park assist; raw 255 = signal not available (SNA)";
CM_ SG_ 907 APP_rearMiddleParkAssist "Driver assistance computer (primary): rear middle park assist; raw 255 = signal not available (SNA)";
CM_ SG_ 907 APP_rearRightMiddleParkAssist "Driver assistance computer (primary): rear right middle park assist; raw 255 = signal not available (SNA)";
CM_ SG_ 907 APP_rearRightParkAssist "Driver assistance computer (primary): rear right park assist; raw 255 = signal not available (SNA)";
CM_ BO_ 605 "Driver assistance computer (primary) message: traffic control";
CM_ SG_ 605 APP_tcFeatureState "The feature level state of stopping for traffic controls";
CM_ SG_ 605 APP_tcStateMachine "The traffic control state machine's internal control state.";
CM_ SG_ 605 APP_tcControlSource "The input data source for the traffic control object";
CM_ SG_ 605 APP_tcControlType "The specific type of traffic control, note not all are control worthy.";
CM_ SG_ 605 APP_tcControlDistance "The distance to the nearest critical traffic control object; raw 255 = signal not available (SNA)";
CM_ SG_ 605 APP_tcControlLightState "Driver assistance computer (primary): tc control light state";
CM_ SG_ 605 APP_tcContinuationReason "The reason the traffic control state machine entered the continue state.";
CM_ SG_ 605 APP_tcConfirmationType "The mechanism of how the driver confirmed the traffic control.";
CM_ SG_ 605 APP_tcWarningSuppressionReason "The suppression reason for the traffic control warning feature.";
CM_ SG_ 605 APP_tcUnavailableReason "The reason why the traffic control feature is currently unavailable.";
CM_ SG_ 605 APP_tcVisionLight "Whether or not the traffic light has a vision measurement.";
CM_ SG_ 605 APP_tcVisionSign "Whether or not the traffic sign has a vision measurement.";
CM_ SG_ 605 APP_tcVisionRoadMarking "Whether or not the road marking has a vision measurement.";
CM_ SG_ 605 APP_tcVisionLine "Whether or not the traffic control line has a vision measurement.";
CM_ BO_ 859 "Driver assistance computer (primary) message: vision ocs status";
CM_ SG_ 859 APP_visionOcsStatusChecksum "Driver assistance computer (primary): vision ocs status checksum";
CM_ SG_ 859 APP_visionOcsStateRaw "Reports classification state raw signal for front passenger from interior camera.";
CM_ SG_ 859 APP_visionOcsEmptyProbRaw "Driver assistance computer (primary): vision ocs empty prob raw; raw 255 = signal not available (SNA)";
CM_ SG_ 859 APP_visionOcsChildProbRaw "Driver assistance computer (primary): vision ocs child prob raw; raw 255 = signal not available (SNA)";
CM_ SG_ 859 APP_visionOcsAdultProbRaw "Driver assistance computer (primary): vision ocs adult prob raw; raw 255 = signal not available (SNA)";
CM_ SG_ 859 APP_visionOcsFrontPasClsVisionSt "Reports classification state of front passenger seat after Bayesian filter.";
CM_ SG_ 859 APP_visionOcsStatusCounter "Driver assistance computer (primary): vision ocs status counter";
CM_ BO_ 637 "Driver assistance computer (secondary) message: eac monitor";
CM_ SG_ 637 APS_eacAllow "Indicates whether or not the Aurix external angle control (EAC) monitor logic currently allows angle control for Autopilot functions; raw 3 = signal not available (SNA)";
CM_ SG_ 637 APS_eacMonitorCounter "Driver assistance computer (secondary): eac monitor counter";
CM_ SG_ 637 APS_eacMonitorChecksum "Driver assistance computer (secondary): eac monitor checksum";
CM_ BO_ 992 "Driver assistance computer (secondary) message: power state inputs";
CM_ SG_ 992 APS_A_lowPowerRequest "Indicates Autopilot Secondary Processor (APS) low power state request presence.";
CM_ SG_ 992 APS_A_lowPowerRequestor "Indicates who initiated the Autopilot Secondary Processor (APS) low power request.";
CM_ SG_ 992 APS_A_forcePowerOffRequest "Driver assistance computer (secondary): a force power off request";
CM_ SG_ 992 APS_B_lowPowerRequest "Indicates Autopilot Secondary Processor (APS) low power state request presence.";
CM_ SG_ 992 APS_B_lowPowerRequestor "Indicates who initiated the Autopilot Secondary Processor (APS) low power request.";
CM_ SG_ 992 APS_B_forcePowerOffRequest "Driver assistance computer (secondary): b force power off request";
CM_ BO_ 1510 "Driver assistance computer (secondary) message: sys health";
CM_ SG_ 1510 APS_A_cam12v0Voltage "Measures the 12V camera power supply voltage for Autopilot Secondary Processor (APS) Turbo A; raw 4095 = signal not available (SNA)";
CM_ SG_ 1510 APS_B_cam12v0Voltage "Measures the 12V camera power supply voltage for Autopilot Secondary Processor (APS) Turbo B; raw 4095 = signal not available (SNA)";
CM_ SG_ 1510 APS_A_turboMaxTemperature "Reports the maximum temperature recorded by Autopilot Secondary Processor (APS) unit A; raw 128 = signal not available (SNA)";
CM_ SG_ 1510 APS_A_turboProbeType "Driver assistance computer (secondary): a turbo probe type; raw 63 = signal not available (SNA)";
CM_ SG_ 1510 APS_B_turboMaxTemperature "Reports the maximum temperature recorded by Autopilot Secondary Processor (APS) unit B; raw 128 = signal not available (SNA)";
CM_ SG_ 1510 APS_B_turboProbeType "Driver assistance computer (secondary): b turbo probe type; raw 63 = signal not available (SNA)";
CM_ BO_ 1497 "Driver assistance computer message: car log";
CM_ SG_ 1497 DAS_carLogMultiplexer "Driver assistance computer: car log multiplexer";
CM_ SG_ 1497 DAS_radarTarget5_dx "Measures the longitudinal distance from the radar to the nearest in-path stationary radar target.";
CM_ SG_ 1497 DAS_radarTarget1_dx "The longitudinal distance from the radar to radar target 1 (closest in-path vehicle)";
CM_ SG_ 1497 DAS_radarTarget1_VxRel "Measures the relative longitudinal velocity to the Adaptive Cruise Control (ACC) radar target 1.";
CM_ SG_ 1497 DAS_mobileyeVehAebFlag "Driver assistance computer: mobileye veh aeb flag";
CM_ SG_ 1497 DAS_mobileyePedAebFlag "Driver assistance computer: mobileye ped aeb flag";
CM_ SG_ 1497 DAS_mobileyeIPSOapproved "Driver assistance computer: mobileye IPS oapproved";
CM_ SG_ 1497 DAS_fcmSteeringOverride "Driver assistance computer: fcm steering override";
CM_ SG_ 1497 DAS_fcmCollisionStage3Checks "Reports the cross checks in the forward collision monitor.";
CM_ SG_ 1497 DAS_fcmThreatAssesmentMode "Driver assistance computer: fcm threat assesment mode";
CM_ SG_ 1497 DAS_constructionArea "Identifies construction area using the output of the 'scene tag' neural net.";
CM_ SG_ 1497 DAS_restrictionLowSpeedTraffic "Reports lane change restriction for low speed traffic.";
CM_ SG_ 1497 DAS_associated_rad_object "Indicates which radar target is associated with the vision object for Forward Collision Mitigation (FCM).";
CM_ SG_ 1497 DAS_LC_handsOnReason "Detects which hands on reason triggered the visual or audible hands-on-warning.";
CM_ SG_ 1497 DAS_ACC_camStatus "Driver assistance computer: ACC cam status";
CM_ SG_ 1497 DAS_aeb_not_activating_reason "Indicates the underlying reason why the next gen LCM AEB did not activate (not yet relevant)";
CM_ SG_ 1497 DAS_handsOnDetected "Driver assistance computer: hands on detected; raw 0 = signal not available (SNA)";
CM_ SG_ 1497 DAS_driveOnNavUnavailableReason "The high level reason why Navigate on Autopilot is not available.";
CM_ SG_ 1497 DAS_accUnavailableReason "The high level reason why ACC is not available.";
CM_ SG_ 1497 DAS_pmmNotActivatingReason "The high level reason why PMM v2 is not activating.";
CM_ SG_ 1497 DAS_desiredTarget_dx "Measures the distance to lead vehicle, or vehicle in the ego lane; raw 255 = signal not available (SNA)";
CM_ SG_ 1497 DAS_radarTarget2_dx "Measures the longitudinal distance from the radar to radar target 2, the 2nd closest in-path vehicle.";
CM_ SG_ 1497 DAS_radarTarget3_dx "Measures the longitudinal distance from the radar to the nearest vehicle in the right lane.";
CM_ SG_ 1497 DAS_radarTarget4_dx "Measures the longitudinal distance from the radar to the nearest vehicle in the left lane.";
CM_ SG_ 1497 DAS_closestInLaneTargetDx "Measures the longitudinal distance from front fascia to closest in-path object.";
CM_ SG_ 1497 DAS_secondInLaneTargetDx "Measures the longitudinal distance from front fascia to 2nd closest in-path object.";
CM_ SG_ 1497 DAS_closestLeftLaneTargetDx "Measures the longitudinal distance from front fascia to closest object in the left lane.";
CM_ SG_ 1497 DAS_closestRightLaneTargetDx "Measures the longitudinal distance from front fascia to closest object in the right lane.";
CM_ SG_ 1497 DAS_closestInLaneTargetVxRel "Measures the relative longitudinal velocity of closest in-path object.";
CM_ BO_ 1337 "Driver assistance computer message: info";
CM_ SG_ 1337 DAS_infoIndex "Driver assistance computer: info index";
CM_ SG_ 1337 DAS_infoBuildType "Driver assistance computer: info build type";
CM_ SG_ 1337 DAS_infoBuildConfigID "Driver assistance computer: info build config ID";
CM_ SG_ 1337 DAS_infoHardwareID "Driver assistance computer: info hardware ID";
CM_ SG_ 1337 DAS_infoComponentID "Driver assistance computer: info component ID";
CM_ SG_ 1337 DAS_infoPcbaID "Driver assistance computer: info pcba ID";
CM_ SG_ 1337 DAS_infoAssemblyID "Driver assistance computer: info assembly ID";
CM_ SG_ 1337 DAS_infoUsageID "Driver assistance computer: info usage ID";
CM_ SG_ 1337 DAS_infoSubUsageID "Driver assistance computer: info sub usage ID";
CM_ SG_ 1337 DAS_infoApplicationCRC "Driver assistance computer: info application CRC";
CM_ SG_ 1337 DAS_infoAppGitHashBytes "Driver assistance computer: info app git hash bytes";
CM_ SG_ 1337 DAS_infoBootGitHashBytes "Driver assistance computer: info boot git hash bytes";
CM_ BO_ 569 "Driver assistance computer message: lanes";
CM_ SG_ 569 DAS_leftLaneExists "Driver assistance computer: left lane exists";
CM_ SG_ 569 DAS_rightLaneExists "Driver assistance computer: right lane exists";
CM_ SG_ 569 DAS_virtualLaneWidth "Driver assistance computer: virtual lane width";
CM_ SG_ 569 DAS_virtualLaneViewRange "Driver assistance computer: virtual lane view range";
CM_ SG_ 569 DAS_virtualLaneC0 "Driver assistance computer: virtual lane C0";
CM_ SG_ 569 DAS_virtualLaneC1 "Driver assistance computer: virtual lane C1";
CM_ SG_ 569 DAS_virtualLaneC2 "Driver assistance computer: virtual lane C2";
CM_ SG_ 569 DAS_virtualLaneC3 "Driver assistance computer: virtual lane C3";
CM_ SG_ 569 DAS_leftLineUsage "Driver assistance computer: left line usage";
CM_ SG_ 569 DAS_rightLineUsage "Driver assistance computer: right line usage";
CM_ SG_ 569 DAS_leftFork "Driver assistance computer: left fork";
CM_ SG_ 569 DAS_rightFork "Driver assistance computer: right fork";
CM_ SG_ 569 DAS_lanesCounter "Driver assistance computer: lanes counter";
CM_ BO_ 921 "Driver assistance computer message: status";
CM_ SG_ 921 DAS_autopilotState "Reports the high level autopilot state; raw 15 = signal not available (SNA)";
CM_ SG_ 921 DAS_blindSpotRearLeft "Reports rear left blind spot warning level; raw 3 = signal not available (SNA)";
CM_ SG_ 921 DAS_blindSpotRearRight "Reports rear right blind spot warning level; raw 3 = signal not available (SNA)";
CM_ SG_ 921 DAS_fusedSpeedLimit "Driver assistance computer: fused speed limit; raw 0 = signal not available (SNA)";
CM_ SG_ 921 DAS_suppressSpeedWarning "Driver assistance computer: suppress speed warning";
CM_ SG_ 921 DAS_summonObstacle "Driver assistance computer: summon obstacle";
CM_ SG_ 921 DAS_summonClearedGate "Driver assistance computer: summon cleared gate";
CM_ SG_ 921 DAS_visionOnlySpeedLimit "Driver assistance computer: vision only speed limit; raw 0 = signal not available (SNA)";
CM_ SG_ 921 DAS_heaterState "The state of the app which runs the front glass heater; raw 0 = signal not available (SNA)";
CM_ SG_ 921 DAS_forwardCollisionWarning "Driver assistance computer: forward collision warning; raw 3 = signal not available (SNA)";
CM_ SG_ 921 DAS_autoparkReady "Indicates if all the conditions for Autopark are met.";
CM_ SG_ 921 DAS_autoParked "Driver assistance computer: auto parked";
CM_ SG_ 921 DAS_autoparkActive "Reports whether Autopark is currently active.";
CM_ SG_ 921 DAS_summonFwdLeashReached "Driver assistance computer: summon fwd leash reached";
CM_ SG_ 921 DAS_summonRvsLeashReached "Driver assistance computer: summon rvs leash reached";
CM_ SG_ 921 DAS_lssState "Tracks lane support system state and whether it is controlling steering angle requests for LKA / ELKA.";
CM_ SG_ 921 DAS_sideCollisionAvoid "Reports if the side collision avoidance function is active on the left or right; raw 3 = signal not available (SNA)";
CM_ SG_ 921 DAS_sideCollisionWarning "Reports if the side collision warning function is active in the left or right.";
CM_ SG_ 921 DAS_sideCollisionInhibit "Driver assistance computer: side collision inhibit";
CM_ SG_ 921 DAS_laneDepartureWarning "Driver assistance computer: lane departure warning; raw 5 = signal not available (SNA)";
CM_ SG_ 921 DAS_fleetSpeedState "The state of the fleet speed algorithm.";
CM_ SG_ 921 DAS_autopilotHandsOnState "Reports the state of the hands on state machine; raw 15 = signal not available (SNA)";
CM_ SG_ 921 DAS_autoLaneChangeState "Reports the legacy Automatic Lane Change (ALC) state used to drive the instrument cluster User Interface (UI); raw 31 = signal not available (SNA)";
CM_ SG_ 921 DAS_summonAvailable "Driver assistance computer: summon available";
CM_ SG_ 921 DAS_statusCounter "Driver assistance computer: status counter";
CM_ SG_ 921 DAS_statusChecksum "Driver assistance computer: status checksum";
CM_ BO_ 905 "Driver assistance computer message: status2";
CM_ SG_ 905 DAS_accSpeedLimit "Reports the Adaptive Cruise Control (ACC) speed limit, which is derived from speed limits embedded in maps; raw 511 = signal not available (SNA)";
CM_ SG_ 905 DAS_versionIdentifier "Driver assistance computer: version identifier";
CM_ SG_ 905 DAS_pmmObstacleSeverity "Detects the output of the Pedal Misapplication Mitigation (PMM) function, which limits torque or applies the brake; raw 7 = signal not available (SNA)";
CM_ SG_ 905 DAS_pmmLoggingRequest "Driver assistance computer: pmm logging request";
CM_ SG_ 905 DAS_activationFailureStatus "Driver assistance computer: activation failure status";
CM_ SG_ 905 DAS_pmmUltrasonicsFaultReason "Reports if there is a reason Pedal Misapplication Mitigation (PMM) is disabled due to a condition with the ultrasonics.";
CM_ SG_ 905 DAS_pmmRadarFaultReason "Reports if there is a reason Pedal Misapplication Mitigation (PMM) is disabled due to a radar issue.";
CM_ SG_ 905 DAS_pmmSysFaultReason "Reports if there is a reason Pedal Misapplication Mitigation (PMM) is disabled due to a system malfunction.";
CM_ SG_ 905 DAS_pmmCameraFaultReason "Reports if there is a reason Pedal Misapplication Mitigation (PMM) is disabled due to camera issues.";
CM_ SG_ 905 DAS_ACC_report "Indicates what control target Traffic-Aware Cruise Control (TACC) is controlling for. Only relevant during TACC (not Autosteer).";
CM_ SG_ 905 DAS_relaxCruiseLimits "Indicates whether DI should relax accel limits";
CM_ SG_ 905 DAS_csaState "Reports the state of the curve speed adaption algorithm.";
CM_ SG_ 905 DAS_radarTelemetry "Driver assistance computer: radar telemetry";
CM_ SG_ 905 DAS_robState "Driver assistance computer: rob state";
CM_ SG_ 905 DAS_driverInteractionLevel "Driver assistance computer: driver interaction level";
CM_ SG_ 905 DAS_ppOffsetDesiredRamp "Driver assistance computer: pp offset desired ramp";
CM_ SG_ 905 DAS_longCollisionWarning "Driver assistance computer: long collision warning; raw 15 = signal not available (SNA)";
CM_ SG_ 905 DAS_status2Counter "Driver assistance computer: status2 counter";
CM_ SG_ 905 DAS_status2Checksum "Driver assistance computer: status2 checksum";
CM_ BO_ 586 "Driver assistance computer message: visual debug";
CM_ SG_ 586 DAS_autosteerVehiclesUsage "Driver assistance computer: autosteer vehicles usage";
CM_ SG_ 586 DAS_autosteerHPPUsage "Driver assistance computer: autosteer HPP usage";
CM_ SG_ 586 DAS_autosteerNavigationUsage "Driver assistance computer: autosteer navigation usage";
CM_ SG_ 586 DAS_autosteerModelUsage "Driver assistance computer: autosteer model usage";
CM_ SG_ 586 DAS_autosteerBottsDotsUsage "Driver assistance computer: autosteer botts dots usage";
CM_ SG_ 586 DAS_offsetSide "Driver assistance computer: offset side";
CM_ SG_ 586 DAS_roadSurfaceType "Driver assistance computer: road surface type; raw 0 = signal not available (SNA)";
CM_ SG_ 586 DAS_autosteerHealthAnomalyLevel "Driver assistance computer: autosteer health anomaly level";
CM_ SG_ 586 DAS_autosteerHealthState "Driver assistance computer: autosteer health state";
CM_ SG_ 586 DAS_lastLinePreferenceReason "Driver assistance computer: last line preference reason";
CM_ SG_ 586 DAS_plannerState "Driver assistance computer: planner state";
CM_ SG_ 586 DAS_lastAutosteerAbortReason "Driver assistance computer: last autosteer abort reason";
CM_ SG_ 586 DAS_devAppInterfaceEnabled "Driver assistance computer: dev app interface enabled";
CM_ SG_ 586 DAS_navAvailable "Driver assistance computer: nav available";
CM_ SG_ 586 DAS_navDistance "Driver assistance computer: nav distance";
CM_ SG_ 586 DAS_accSmartSpeedActive "Driver assistance computer: acc smart speed active";
CM_ SG_ 586 DAS_accSmartSpeedState "Driver assistance computer: acc smart speed state; raw 7 = signal not available (SNA)";
CM_ SG_ 586 DAS_ulcInProgress "Reports active lane changes that were not commanded.";
CM_ SG_ 586 DAS_trafficAwareSetSpeedInUse "Indicates that autopilot is using cruise set speed based on flow of traffic";
CM_ SG_ 586 DAS_isaSystemState "ISA system state";
CM_ SG_ 586 DAS_behaviorType "Driver assistance computer: behavior type";
CM_ SG_ 586 DAS_ulcType "Reports the underlying reason for the uncommanded lane change, whether for speed or route.";
CM_ SG_ 586 DAS_rearVehDetectedThisCycle "Driver assistance computer: rear veh detected this cycle";
CM_ SG_ 586 DAS_rearLeftVehDetectedCurrent "Driver assistance computer: rear left veh detected current";
CM_ SG_ 586 DAS_rearRightVehDetectedTrip "Driver assistance computer: rear right veh detected trip";
CM_ SG_ 586 DAS_rearLeftVehDetectedTrip "Driver assistance computer: rear left veh detected trip";
CM_ BO_ 977 "Electric power steering (secondary) message: angle calibration";
CM_ SG_ 977 EPAS3S_appliedAngleOffset "This represents the angle delta between the absolute steering angle reference and what EPAS estimates to be straight ahead. The steering angle offset can change up to 5deg at the beginning of each drive cycle.";
CM_ SG_ 977 EPAS3S_calculatedAngleOffset "Reports the calculated steering angle offset learned between the Steering Column Control Module (SCCM) and the Electronic Power Assist Steering (EPAS) steering angle.";
CM_ SG_ 977 EPAS3S_resyncStatus "Electric power steering (secondary): resync status";
CM_ SG_ 977 EPAS3S_pullDriftLongTermTrq "The learned, long term pull drift or road crown compensation torque that the rack is applying to the steering wheel.";
CM_ SG_ 977 EPAS3S_pullDriftCompTrq "The current pull drift or road crown compensation torque that the rack is applying to the steering wheel.";
CM_ SG_ 977 EPAS3S_learnedSCCMOffset "Electric power steering (secondary): learned SCCM offset";
CM_ BO_ 785 "Electric power steering (secondary) message: info";
CM_ SG_ 785 EPAS3S_infoIndex "Electric power steering (secondary): info index";
CM_ SG_ 785 EPAS3S_infoBuildType "Electric power steering (secondary): info build type";
CM_ SG_ 785 EPAS3S_infoComponentID "Electric power steering (secondary): info component ID";
CM_ SG_ 785 EPAS3S_infoPcbaID "Electric power steering (secondary): info pcba ID";
CM_ SG_ 785 EPAS3S_infoAssemblyID "Electric power steering (secondary): info assembly ID";
CM_ SG_ 785 EPAS3S_infoUsageID "Electric power steering (secondary): info usage ID";
CM_ SG_ 785 EPAS3S_infoApplicationCRC "Electric power steering (secondary): info application CRC";
CM_ SG_ 785 EPAS3S_infoBootUdsProtoVersion "Electric power steering (secondary): info boot uds proto version";
CM_ SG_ 785 EPAS3S_infoBootloaderCRC "Electric power steering (secondary): info bootloader CRC";
CM_ SG_ 785 EPAS3S_infoSubcomponent2 "Electric power steering (secondary): info subcomponent2";
CM_ BO_ 805 "Electronic stability control message: info";
CM_ SG_ 805 ESP_infoIndex "Electronic stability control: info index";
CM_ SG_ 805 ESP_infoBuildType "Electronic stability control: info build type";
CM_ SG_ 805 ESP_infoComponentID "Electronic stability control: info component ID";
CM_ SG_ 805 ESP_infoPcbaID "Electronic stability control: info pcba ID";
CM_ SG_ 805 ESP_infoAssemblyID "Electronic stability control: info assembly ID";
CM_ SG_ 805 ESP_infoUsageID "Electronic stability control: info usage ID";
CM_ SG_ 805 ESP_infoSubUsageID "Electronic stability control: info sub usage ID";
CM_ SG_ 805 ESP_infoApplicationCRC "Indicating the Application CRC value of firmware running in system.";
CM_ SG_ 805 ESP_infoVehicleVariant "Electronic stability control: info vehicle variant";
CM_ SG_ 805 ESP_infoSubcomponent1 "Electronic stability control: info subcomponent1";
CM_ SG_ 805 ESP_infoBootUdsProtoVersion "Electronic stability control: info boot uds proto version";
CM_ SG_ 805 ESP_infoBootloaderCRC "Electronic stability control: info bootloader CRC";
CM_ SG_ 805 ESP_infoVariantCRC "Indicating the Calibration CRC value of firmware running in system.";
CM_ BO_ 813 "Electric brake booster message: info";
CM_ SG_ 813 IBST_infoIndex "Electric brake booster: info index";
CM_ SG_ 813 IBST_infoBuildType "Electric brake booster: info build type";
CM_ SG_ 813 IBST_infoComponentID "Electric brake booster: info component ID";
CM_ SG_ 813 IBST_infoPcbaID "Electric brake booster: info pcba ID";
CM_ SG_ 813 IBST_infoAssemblyID "Electric brake booster: info assembly ID";
CM_ SG_ 813 IBST_infoUsageID "Electric brake booster: info usage ID";
CM_ SG_ 813 IBST_infoSubUsageID "Electric brake booster: info sub usage ID";
CM_ SG_ 813 IBST_infoApplicationCRC "Indicating the Application CRC value of firmware running in system.";
CM_ SG_ 813 IBST_infoBootUdsProtoVersion "Electric brake booster: info boot uds proto version";
CM_ SG_ 813 IBST_infoBootloaderCRC "Electric brake booster: info bootloader CRC";
CM_ SG_ 813 IBST_infoVariantCRC "Indicating the Calibration CRC value of firmware running in system.";
CM_ BO_ 806 "Parking assist sensors message: info";
CM_ SG_ 806 PARK_infoIndex "Parking assist sensors: info index";
CM_ SG_ 806 PARK_infoBuildType "Parking assist sensors: info build type";
CM_ SG_ 806 PARK_infoComponentID "Parking assist sensors: info component ID";
CM_ SG_ 806 PARK_infoPcbaID "Parking assist sensors: info pcba ID";
CM_ SG_ 806 PARK_infoAssemblyID "Parking assist sensors: info assembly ID";
CM_ SG_ 806 PARK_infoUsageID "Parking assist sensors: info usage ID";
CM_ SG_ 806 PARK_infoApplicationCRC "Parking assist sensors: info application CRC";
CM_ SG_ 806 PARK_infoBootUdsProtoVersion "Parking assist sensors: info boot uds proto version";
CM_ SG_ 806 PARK_infoBootloaderCRC "Parking assist sensors: info bootloader CRC";
CM_ BO_ 846 "Parking assist sensors message: pas front middle";
CM_ SG_ 846 PARK_frontLeftMiddleRawDistData "Zone defined as -38 degrees -> +12 degrees, distance to object in units of centimeters; raw 255 = signal not available (SNA)";
CM_ SG_ 846 PARK_frontMiddleRawDistData "Zone defined as -12 degrees to +12 degrees, distance to object in units of centimeters; raw 255 = signal not available (SNA)";
CM_ SG_ 846 PARK_frontRightMiddleRawDistData "Zone defined +12 degrees to +38 degreees, distance to object in units of centimeters; raw 255 = signal not available (SNA)";
CM_ SG_ 846 PARK_pasFrontMiddleCounter "Parking assist sensors: pas front middle counter";
CM_ SG_ 846 PARK_pasFrontMiddleChecksum "Parking assist sensors: pas front middle checksum";
CM_ BO_ 926 "Parking assist sensors message: pas sides";
CM_ SG_ 926 PARK_rightSideFrontRawDistData "Right side (from inside the car) towards the front of the car (split evenly between axles); raw 255 = signal not available (SNA)";
CM_ SG_ 926 PARK_rightSideRearRawDistData "Right side (from inside the car) towards the rear of the car (split evenly between axles); raw 255 = signal not available (SNA)";
CM_ SG_ 926 PARK_leftSideFrontRawDistData "Left side (from inside the car) towards the front of the car (split evenly between axles); raw 255 = signal not available (SNA)";
CM_ SG_ 926 PARK_leftSideRearRawDistData "Left side (from inside the car) towards the rear of the car (split evenly between axles); raw 255 = signal not available (SNA)";
CM_ SG_ 926 PARK_pasSidesCounter "Parking assist sensors: pas sides counter";
CM_ SG_ 926 PARK_pasSidesChecksum "Parking assist sensors: pas sides checksum";
BA_DEF_ "BusType" STRING;
BA_DEF_ "DBName" STRING;
BA_DEF_ "Baudrate" INT 0 1000000;
BA_DEF_ "BaudrateCANFD" INT 0 16000000;
BA_DEF_ "Manufacturer" STRING;
BA_DEF_ "FirmwareVersion" STRING;
BA_DEF_ "VehicleModel" STRING;
BA_DEF_ BU_ "ECU" STRING;
BA_DEF_ BO_ "GenMsgCycleTime" INT 0 3600000;
BA_DEF_ BO_ "GenMsgSendType" ENUM "Cyclic","NotUsed","NotUsed","NotUsed","NotUsed","NotUsed","NotUsed","IfActive","NoMsgSendType","NotUsed";
BA_DEF_ BO_ "VFrameFormat" ENUM "StandardCAN","ExtendedCAN","reserved","J1939PG","reserved","reserved","reserved","reserved","reserved","reserved","reserved","reserved","reserved","reserved","StandardCAN_FD","ExtendedCAN_FD";
BA_DEF_ BO_ "CANFD_BRS" ENUM "0","1";
BA_DEF_ SG_ "GenSigSNA" STRING;
BA_DEF_ SG_ "SystemSignalLongSymbol" STRING;
BA_DEF_ SG_ "Confidence" ENUM "validated","plausible","layout-only","contradicted";
BA_DEF_DEF_ "BusType" "CAN";
BA_DEF_DEF_ "DBName" "";
BA_DEF_DEF_ "Baudrate" 500000;
BA_DEF_DEF_ "BaudrateCANFD" 2000000;
BA_DEF_DEF_ "Manufacturer" "";
BA_DEF_DEF_ "FirmwareVersion" "";
BA_DEF_DEF_ "VehicleModel" "";
BA_DEF_DEF_ "ECU" "";
BA_DEF_DEF_ "GenMsgCycleTime" 0;
BA_DEF_DEF_ "GenMsgSendType" "NoMsgSendType";
BA_DEF_DEF_ "VFrameFormat" "StandardCAN";
BA_DEF_DEF_ "CANFD_BRS" "1";
BA_DEF_DEF_ "GenSigSNA" "";
BA_DEF_DEF_ "SystemSignalLongSymbol" "";
BA_DEF_DEF_ "Confidence" "layout-only";
BA_ "DBName" "Model3_CH";
BA_ "Manufacturer" "Tesla";
BA_ "FirmwareVersion" "2025.20.8";
BA_ "VehicleModel" "Model 3";
BA_ "ECU" BU_ APP "APP";
BA_ "ECU" BU_ APS "APS";
BA_ "ECU" BU_ DAS "DAS";
BA_ "ECU" BU_ EPAS3S "EPAS3S";
BA_ "ECU" BU_ ESP "ESP";
BA_ "ECU" BU_ GTW "GTW";
BA_ "ECU" BU_ IBST "IBST";
BA_ "ECU" BU_ PARK "PARK";
BA_ "ECU" BU_ RADC "RADC";
BA_ "ECU" BU_ RCM "RCM";
BA_ "ECU" BU_ TPMS "TPMS";
BA_ "ECU" BU_ USM "USM";
BA_ "GenMsgCycleTime" BO_ 1045 500;
BA_ "GenMsgSendType" BO_ 1045 0;
BA_ "GenMsgCycleTime" BO_ 1020 1000;
BA_ "GenMsgSendType" BO_ 1020 0;
BA_ "GenMsgCycleTime" BO_ 1018 500;
BA_ "GenMsgSendType" BO_ 1018 0;
BA_ "GenMsgCycleTime" BO_ 1043 500;
BA_ "GenMsgSendType" BO_ 1043 0;
BA_ "GenMsgCycleTime" BO_ 1061 1000;
BA_ "GenMsgSendType" BO_ 1061 0;
BA_ "GenMsgCycleTime" BO_ 843 100;
BA_ "GenMsgSendType" BO_ 843 0;
BA_ "GenMsgCycleTime" BO_ 1353 1000;
BA_ "GenMsgSendType" BO_ 1353 0;
BA_ "GenMsgCycleTime" BO_ 907 100;
BA_ "GenMsgSendType" BO_ 907 0;
BA_ "GenMsgCycleTime" BO_ 605 500;
BA_ "GenMsgSendType" BO_ 605 0;
BA_ "GenMsgCycleTime" BO_ 859 100;
BA_ "GenMsgSendType" BO_ 859 0;
BA_ "GenMsgCycleTime" BO_ 637 100;
BA_ "GenMsgSendType" BO_ 637 0;
BA_ "GenMsgCycleTime" BO_ 992 100;
BA_ "GenMsgSendType" BO_ 992 0;
BA_ "GenMsgCycleTime" BO_ 1510 1000;
BA_ "GenMsgSendType" BO_ 1510 0;
BA_ "GenMsgCycleTime" BO_ 1497 333;
BA_ "GenMsgSendType" BO_ 1497 0;
BA_ "GenMsgCycleTime" BO_ 1337 1000;
BA_ "GenMsgSendType" BO_ 1337 0;
BA_ "GenMsgCycleTime" BO_ 569 100;
BA_ "GenMsgSendType" BO_ 569 0;
BA_ "GenMsgCycleTime" BO_ 921 500;
BA_ "GenMsgSendType" BO_ 921 0;
BA_ "GenMsgCycleTime" BO_ 905 500;
BA_ "GenMsgSendType" BO_ 905 0;
BA_ "GenMsgCycleTime" BO_ 586 100;
BA_ "GenMsgSendType" BO_ 586 0;
BA_ "GenMsgCycleTime" BO_ 977 1000;
BA_ "GenMsgSendType" BO_ 977 0;
BA_ "GenMsgCycleTime" BO_ 785 1000;
BA_ "GenMsgSendType" BO_ 785 0;
BA_ "GenMsgCycleTime" BO_ 805 10000;
BA_ "GenMsgSendType" BO_ 805 0;
BA_ "GenMsgCycleTime" BO_ 813 10000;
BA_ "GenMsgSendType" BO_ 813 0;
BA_ "GenMsgCycleTime" BO_ 806 1000;
BA_ "GenMsgSendType" BO_ 806 0;
BA_ "GenMsgCycleTime" BO_ 846 100;
BA_ "GenMsgSendType" BO_ 846 0;
BA_ "GenMsgCycleTime" BO_ 926 100;
BA_ "GenMsgSendType" BO_ 926 0;
BA_ "Confidence" SG_ 1045 APP_backupDashCamFeedGood 0;
BA_ "Confidence" SG_ 1045 APP_backupDashCamFrameRate 0;
BA_ "Confidence" SG_ 1020 APP_decisionTemperature 0;
BA_ "Confidence" SG_ 1020 APP_pascalTemperature 0;
BA_ "Confidence" SG_ 1020 APP_parkerATemperature 0;
BA_ "Confidence" SG_ 1020 APP_parkerBTemperature 0;
BA_ "Confidence" SG_ 1020 APP_pascalExtTemperature 0;
BA_ "Confidence" SG_ 1020 APP_parkerExtTemperature 0;
BA_ "Confidence" SG_ 1020 APP_pascalHeaterDecision 0;
BA_ "Confidence" SG_ 1018 APP_mainCameraLUX 0;
BA_ "GenSigSNA" SG_ 1018 APP_mainCameraLUX "255";
BA_ "Confidence" SG_ 1018 APP_narrowCameraLUX 0;
BA_ "GenSigSNA" SG_ 1018 APP_narrowCameraLUX "255";
BA_ "Confidence" SG_ 1018 APP_fisheyeCameraLUX 0;
BA_ "GenSigSNA" SG_ 1018 APP_fisheyeCameraLUX "255";
BA_ "Confidence" SG_ 1018 APP_lRepeatCameraLUX 0;
BA_ "GenSigSNA" SG_ 1018 APP_lRepeatCameraLUX "255";
BA_ "Confidence" SG_ 1018 APP_rRepeatCameraLUX 0;
BA_ "GenSigSNA" SG_ 1018 APP_rRepeatCameraLUX "255";
BA_ "Confidence" SG_ 1018 APP_lPillarCameraLUX 0;
BA_ "GenSigSNA" SG_ 1018 APP_lPillarCameraLUX "255";
BA_ "Confidence" SG_ 1018 APP_rPillarCameraLUX 0;
BA_ "GenSigSNA" SG_ 1018 APP_rPillarCameraLUX "255";
BA_ "Confidence" SG_ 1018 APP_backupCameraLUX 0;
BA_ "GenSigSNA" SG_ 1018 APP_backupCameraLUX "255";
BA_ "Confidence" SG_ 1043 APP_mainDashCamFeedGood 0;
BA_ "Confidence" SG_ 1043 APP_mainDashCamFrameRate 0;
BA_ "Confidence" SG_ 1043 APP_lRepeatDashCamFeedGood 0;
BA_ "Confidence" SG_ 1043 APP_lRepeatDashCamFrameRate 0;
BA_ "Confidence" SG_ 1043 APP_rRepeatDashCamFeedGood 0;
BA_ "Confidence" SG_ 1043 APP_rRepeatDashCamFrameRate 0;
BA_ "Confidence" SG_ 1061 APP_factoryGoalLatitude 0;
BA_ "Confidence" SG_ 1061 APP_factoryGoalLongitude 0;
BA_ "Confidence" SG_ 1061 APP_factoryGoalSpeed 0;
BA_ "Confidence" SG_ 843 APP_frontLeftParkAssist 0;
BA_ "GenSigSNA" SG_ 843 APP_frontLeftParkAssist "255";
BA_ "Confidence" SG_ 843 APP_frontLeftMiddleParkAssist 0;
BA_ "GenSigSNA" SG_ 843 APP_frontLeftMiddleParkAssist "255";
BA_ "Confidence" SG_ 843 APP_frontMiddleParkAssist 0;
BA_ "GenSigSNA" SG_ 843 APP_frontMiddleParkAssist "255";
BA_ "Confidence" SG_ 843 APP_frontRightMiddleParkAssist 0;
BA_ "GenSigSNA" SG_ 843 APP_frontRightMiddleParkAssist "255";
BA_ "Confidence" SG_ 843 APP_frontRightParkAssist 0;
BA_ "GenSigSNA" SG_ 843 APP_frontRightParkAssist "255";
BA_ "Confidence" SG_ 843 APP_parkAssistStatus 0;
BA_ "GenSigSNA" SG_ 843 APP_parkAssistStatus "3";
BA_ "Confidence" SG_ 843 APP_useParkDistancesFromAP 0;
BA_ "Confidence" SG_ 1353 APP_infoIndex 1;
BA_ "Confidence" SG_ 1353 APP_buildType 0;
BA_ "Confidence" SG_ 907 APP_rearLeftParkAssist 0;
BA_ "GenSigSNA" SG_ 907 APP_rearLeftParkAssist "255";
BA_ "Confidence" SG_ 907 APP_rearLeftMiddleParkAssist 0;
BA_ "GenSigSNA" SG_ 907 APP_rearLeftMiddleParkAssist "255";
BA_ "Confidence" SG_ 907 APP_rearMiddleParkAssist 0;
BA_ "GenSigSNA" SG_ 907 APP_rearMiddleParkAssist "255";
BA_ "Confidence" SG_ 907 APP_rearRightMiddleParkAssist 0;
BA_ "GenSigSNA" SG_ 907 APP_rearRightMiddleParkAssist "255";
BA_ "Confidence" SG_ 907 APP_rearRightParkAssist 0;
BA_ "GenSigSNA" SG_ 907 APP_rearRightParkAssist "255";
BA_ "Confidence" SG_ 605 APP_tcFeatureState 0;
BA_ "Confidence" SG_ 605 APP_tcStateMachine 0;
BA_ "Confidence" SG_ 605 APP_tcControlSource 0;
BA_ "Confidence" SG_ 605 APP_tcControlType 0;
BA_ "Confidence" SG_ 605 APP_tcControlDistance 0;
BA_ "GenSigSNA" SG_ 605 APP_tcControlDistance "255";
BA_ "Confidence" SG_ 605 APP_tcControlLightState 0;
BA_ "Confidence" SG_ 605 APP_tcContinuationReason 0;
BA_ "Confidence" SG_ 605 APP_tcConfirmationType 0;
BA_ "Confidence" SG_ 605 APP_tcWarningSuppressionReason 0;
BA_ "Confidence" SG_ 605 APP_tcUnavailableReason 0;
BA_ "Confidence" SG_ 605 APP_tcVisionLight 0;
BA_ "Confidence" SG_ 605 APP_tcVisionSign 0;
BA_ "Confidence" SG_ 605 APP_tcVisionRoadMarking 0;
BA_ "Confidence" SG_ 605 APP_tcVisionLine 0;
BA_ "Confidence" SG_ 859 APP_visionOcsStatusChecksum 0;
BA_ "Confidence" SG_ 859 APP_visionOcsStateRaw 0;
BA_ "Confidence" SG_ 859 APP_visionOcsEmptyProbRaw 0;
BA_ "GenSigSNA" SG_ 859 APP_visionOcsEmptyProbRaw "255";
BA_ "Confidence" SG_ 859 APP_visionOcsChildProbRaw 0;
BA_ "GenSigSNA" SG_ 859 APP_visionOcsChildProbRaw "255";
BA_ "Confidence" SG_ 859 APP_visionOcsAdultProbRaw 0;
BA_ "GenSigSNA" SG_ 859 APP_visionOcsAdultProbRaw "255";
BA_ "Confidence" SG_ 859 APP_visionOcsFrontPasClsVisionSt 0;
BA_ "SystemSignalLongSymbol" SG_ 859 APP_visionOcsFrontPasClsVisionSt "APP_visionOcsFrontPasClsVisionStateFlt";
BA_ "Confidence" SG_ 859 APP_visionOcsStatusCounter 0;
BA_ "Confidence" SG_ 637 APS_eacAllow 0;
BA_ "GenSigSNA" SG_ 637 APS_eacAllow "3";
BA_ "Confidence" SG_ 637 APS_eacMonitorCounter 0;
BA_ "Confidence" SG_ 637 APS_eacMonitorChecksum 0;
BA_ "Confidence" SG_ 992 APS_A_lowPowerRequest 0;
BA_ "Confidence" SG_ 992 APS_A_lowPowerRequestor 0;
BA_ "Confidence" SG_ 992 APS_A_forcePowerOffRequest 0;
BA_ "Confidence" SG_ 992 APS_B_lowPowerRequest 0;
BA_ "Confidence" SG_ 992 APS_B_lowPowerRequestor 0;
BA_ "Confidence" SG_ 992 APS_B_forcePowerOffRequest 0;
BA_ "Confidence" SG_ 1510 APS_A_cam12v0Voltage 0;
BA_ "GenSigSNA" SG_ 1510 APS_A_cam12v0Voltage "4095";
BA_ "Confidence" SG_ 1510 APS_B_cam12v0Voltage 0;
BA_ "GenSigSNA" SG_ 1510 APS_B_cam12v0Voltage "4095";
BA_ "Confidence" SG_ 1510 APS_A_turboMaxTemperature 0;
BA_ "GenSigSNA" SG_ 1510 APS_A_turboMaxTemperature "128";
BA_ "Confidence" SG_ 1510 APS_A_turboProbeType 0;
BA_ "GenSigSNA" SG_ 1510 APS_A_turboProbeType "63";
BA_ "Confidence" SG_ 1510 APS_B_turboMaxTemperature 0;
BA_ "GenSigSNA" SG_ 1510 APS_B_turboMaxTemperature "128";
BA_ "Confidence" SG_ 1510 APS_B_turboProbeType 0;
BA_ "GenSigSNA" SG_ 1510 APS_B_turboProbeType "63";
BA_ "Confidence" SG_ 1497 DAS_carLogMultiplexer 1;
BA_ "Confidence" SG_ 1497 DAS_radarTarget5_dx 0;
BA_ "Confidence" SG_ 1497 DAS_radarTarget1_dx 0;
BA_ "Confidence" SG_ 1497 DAS_radarTarget1_VxRel 0;
BA_ "Confidence" SG_ 1497 DAS_mobileyeVehAebFlag 0;
BA_ "Confidence" SG_ 1497 DAS_mobileyePedAebFlag 0;
BA_ "Confidence" SG_ 1497 DAS_mobileyeIPSOapproved 0;
BA_ "Confidence" SG_ 1497 DAS_fcmSteeringOverride 0;
BA_ "Confidence" SG_ 1497 DAS_fcmCollisionStage3Checks 0;
BA_ "Confidence" SG_ 1497 DAS_fcmThreatAssesmentMode 0;
BA_ "Confidence" SG_ 1497 DAS_constructionArea 0;
BA_ "Confidence" SG_ 1497 DAS_restrictionLowSpeedTraffic 0;
BA_ "Confidence" SG_ 1497 DAS_associated_rad_object 0;
BA_ "Confidence" SG_ 1497 DAS_LC_handsOnReason 0;
BA_ "Confidence" SG_ 1497 DAS_ACC_camStatus 0;
BA_ "Confidence" SG_ 1497 DAS_aeb_not_activating_reason 0;
BA_ "Confidence" SG_ 1497 DAS_handsOnDetected 0;
BA_ "GenSigSNA" SG_ 1497 DAS_handsOnDetected "0";
BA_ "Confidence" SG_ 1497 DAS_driveOnNavUnavailableReason 0;
BA_ "Confidence" SG_ 1497 DAS_accUnavailableReason 0;
BA_ "Confidence" SG_ 1497 DAS_pmmNotActivatingReason 0;
BA_ "Confidence" SG_ 1497 DAS_desiredTarget_dx 0;
BA_ "GenSigSNA" SG_ 1497 DAS_desiredTarget_dx "255";
BA_ "Confidence" SG_ 1497 DAS_radarTarget2_dx 0;
BA_ "Confidence" SG_ 1497 DAS_radarTarget3_dx 0;
BA_ "Confidence" SG_ 1497 DAS_radarTarget4_dx 0;
BA_ "Confidence" SG_ 1497 DAS_closestInLaneTargetDx 0;
BA_ "Confidence" SG_ 1497 DAS_secondInLaneTargetDx 0;
BA_ "Confidence" SG_ 1497 DAS_closestLeftLaneTargetDx 0;
BA_ "Confidence" SG_ 1497 DAS_closestRightLaneTargetDx 0;
BA_ "Confidence" SG_ 1497 DAS_closestInLaneTargetVxRel 0;
BA_ "Confidence" SG_ 1337 DAS_infoIndex 1;
BA_ "Confidence" SG_ 1337 DAS_infoBuildType 0;
BA_ "Confidence" SG_ 1337 DAS_infoBuildConfigID 0;
BA_ "Confidence" SG_ 1337 DAS_infoHardwareID 0;
BA_ "Confidence" SG_ 1337 DAS_infoComponentID 0;
BA_ "Confidence" SG_ 1337 DAS_infoPcbaID 0;
BA_ "Confidence" SG_ 1337 DAS_infoAssemblyID 0;
BA_ "Confidence" SG_ 1337 DAS_infoUsageID 0;
BA_ "Confidence" SG_ 1337 DAS_infoSubUsageID 0;
BA_ "Confidence" SG_ 1337 DAS_infoApplicationCRC 0;
BA_ "Confidence" SG_ 1337 DAS_infoAppGitHashBytes 0;
BA_ "Confidence" SG_ 1337 DAS_infoBootGitHashBytes 0;
BA_ "Confidence" SG_ 569 DAS_leftLaneExists 0;
BA_ "Confidence" SG_ 569 DAS_rightLaneExists 0;
BA_ "Confidence" SG_ 569 DAS_virtualLaneWidth 0;
BA_ "Confidence" SG_ 569 DAS_virtualLaneViewRange 0;
BA_ "Confidence" SG_ 569 DAS_virtualLaneC0 0;
BA_ "Confidence" SG_ 569 DAS_virtualLaneC1 0;
BA_ "Confidence" SG_ 569 DAS_virtualLaneC2 0;
BA_ "Confidence" SG_ 569 DAS_virtualLaneC3 0;
BA_ "Confidence" SG_ 569 DAS_leftLineUsage 0;
BA_ "Confidence" SG_ 569 DAS_rightLineUsage 0;
BA_ "Confidence" SG_ 569 DAS_leftFork 0;
BA_ "Confidence" SG_ 569 DAS_rightFork 0;
BA_ "Confidence" SG_ 569 DAS_lanesCounter 0;
BA_ "Confidence" SG_ 921 DAS_autopilotState 0;
BA_ "GenSigSNA" SG_ 921 DAS_autopilotState "15";
BA_ "Confidence" SG_ 921 DAS_blindSpotRearLeft 0;
BA_ "GenSigSNA" SG_ 921 DAS_blindSpotRearLeft "3";
BA_ "Confidence" SG_ 921 DAS_blindSpotRearRight 0;
BA_ "GenSigSNA" SG_ 921 DAS_blindSpotRearRight "3";
BA_ "Confidence" SG_ 921 DAS_fusedSpeedLimit 0;
BA_ "GenSigSNA" SG_ 921 DAS_fusedSpeedLimit "0";
BA_ "Confidence" SG_ 921 DAS_suppressSpeedWarning 0;
BA_ "Confidence" SG_ 921 DAS_summonObstacle 0;
BA_ "Confidence" SG_ 921 DAS_summonClearedGate 0;
BA_ "Confidence" SG_ 921 DAS_visionOnlySpeedLimit 0;
BA_ "GenSigSNA" SG_ 921 DAS_visionOnlySpeedLimit "0";
BA_ "Confidence" SG_ 921 DAS_heaterState 0;
BA_ "GenSigSNA" SG_ 921 DAS_heaterState "0";
BA_ "Confidence" SG_ 921 DAS_forwardCollisionWarning 0;
BA_ "GenSigSNA" SG_ 921 DAS_forwardCollisionWarning "3";
BA_ "Confidence" SG_ 921 DAS_autoparkReady 0;
BA_ "Confidence" SG_ 921 DAS_autoParked 0;
BA_ "Confidence" SG_ 921 DAS_autoparkActive 0;
BA_ "Confidence" SG_ 921 DAS_summonFwdLeashReached 0;
BA_ "Confidence" SG_ 921 DAS_summonRvsLeashReached 0;
BA_ "Confidence" SG_ 921 DAS_lssState 0;
BA_ "Confidence" SG_ 921 DAS_sideCollisionAvoid 0;
BA_ "GenSigSNA" SG_ 921 DAS_sideCollisionAvoid "3";
BA_ "Confidence" SG_ 921 DAS_sideCollisionWarning 0;
BA_ "Confidence" SG_ 921 DAS_sideCollisionInhibit 0;
BA_ "Confidence" SG_ 921 DAS_laneDepartureWarning 0;
BA_ "GenSigSNA" SG_ 921 DAS_laneDepartureWarning "5";
BA_ "Confidence" SG_ 921 DAS_fleetSpeedState 0;
BA_ "Confidence" SG_ 921 DAS_autopilotHandsOnState 0;
BA_ "GenSigSNA" SG_ 921 DAS_autopilotHandsOnState "15";
BA_ "Confidence" SG_ 921 DAS_autoLaneChangeState 0;
BA_ "GenSigSNA" SG_ 921 DAS_autoLaneChangeState "31";
BA_ "Confidence" SG_ 921 DAS_summonAvailable 0;
BA_ "Confidence" SG_ 921 DAS_statusCounter 0;
BA_ "Confidence" SG_ 921 DAS_statusChecksum 0;
BA_ "Confidence" SG_ 905 DAS_accSpeedLimit 0;
BA_ "GenSigSNA" SG_ 905 DAS_accSpeedLimit "511";
BA_ "Confidence" SG_ 905 DAS_versionIdentifier 0;
BA_ "Confidence" SG_ 905 DAS_pmmObstacleSeverity 0;
BA_ "GenSigSNA" SG_ 905 DAS_pmmObstacleSeverity "7";
BA_ "Confidence" SG_ 905 DAS_pmmLoggingRequest 0;
BA_ "Confidence" SG_ 905 DAS_activationFailureStatus 0;
BA_ "Confidence" SG_ 905 DAS_pmmUltrasonicsFaultReason 0;
BA_ "Confidence" SG_ 905 DAS_pmmRadarFaultReason 0;
BA_ "Confidence" SG_ 905 DAS_pmmSysFaultReason 0;
BA_ "Confidence" SG_ 905 DAS_pmmCameraFaultReason 0;
BA_ "Confidence" SG_ 905 DAS_ACC_report 0;
BA_ "Confidence" SG_ 905 DAS_relaxCruiseLimits 0;
BA_ "Confidence" SG_ 905 DAS_csaState 0;
BA_ "Confidence" SG_ 905 DAS_radarTelemetry 0;
BA_ "Confidence" SG_ 905 DAS_robState 0;
BA_ "Confidence" SG_ 905 DAS_driverInteractionLevel 0;
BA_ "Confidence" SG_ 905 DAS_ppOffsetDesiredRamp 0;
BA_ "Confidence" SG_ 905 DAS_longCollisionWarning 0;
BA_ "GenSigSNA" SG_ 905 DAS_longCollisionWarning "15";
BA_ "Confidence" SG_ 905 DAS_status2Counter 0;
BA_ "Confidence" SG_ 905 DAS_status2Checksum 0;
BA_ "Confidence" SG_ 586 DAS_autosteerVehiclesUsage 0;
BA_ "Confidence" SG_ 586 DAS_autosteerHPPUsage 0;
BA_ "Confidence" SG_ 586 DAS_autosteerNavigationUsage 0;
BA_ "Confidence" SG_ 586 DAS_autosteerModelUsage 0;
BA_ "Confidence" SG_ 586 DAS_autosteerBottsDotsUsage 0;
BA_ "Confidence" SG_ 586 DAS_offsetSide 0;
BA_ "Confidence" SG_ 586 DAS_roadSurfaceType 0;
BA_ "GenSigSNA" SG_ 586 DAS_roadSurfaceType "0";
BA_ "Confidence" SG_ 586 DAS_autosteerHealthAnomalyLevel 0;
BA_ "Confidence" SG_ 586 DAS_autosteerHealthState 0;
BA_ "Confidence" SG_ 586 DAS_lastLinePreferenceReason 0;
BA_ "Confidence" SG_ 586 DAS_plannerState 0;
BA_ "Confidence" SG_ 586 DAS_lastAutosteerAbortReason 0;
BA_ "Confidence" SG_ 586 DAS_devAppInterfaceEnabled 0;
BA_ "Confidence" SG_ 586 DAS_navAvailable 0;
BA_ "Confidence" SG_ 586 DAS_navDistance 0;
BA_ "Confidence" SG_ 586 DAS_accSmartSpeedActive 0;
BA_ "Confidence" SG_ 586 DAS_accSmartSpeedState 0;
BA_ "GenSigSNA" SG_ 586 DAS_accSmartSpeedState "7";
BA_ "Confidence" SG_ 586 DAS_ulcInProgress 0;
BA_ "Confidence" SG_ 586 DAS_trafficAwareSetSpeedInUse 0;
BA_ "Confidence" SG_ 586 DAS_isaSystemState 0;
BA_ "Confidence" SG_ 586 DAS_behaviorType 0;
BA_ "Confidence" SG_ 586 DAS_ulcType 0;
BA_ "Confidence" SG_ 586 DAS_rearVehDetectedThisCycle 0;
BA_ "Confidence" SG_ 586 DAS_rearLeftVehDetectedCurrent 0;
BA_ "Confidence" SG_ 586 DAS_rearRightVehDetectedTrip 0;
BA_ "Confidence" SG_ 586 DAS_rearLeftVehDetectedTrip 0;
BA_ "Confidence" SG_ 977 EPAS3S_appliedAngleOffset 0;
BA_ "Confidence" SG_ 977 EPAS3S_calculatedAngleOffset 0;
BA_ "Confidence" SG_ 977 EPAS3S_resyncStatus 0;
BA_ "Confidence" SG_ 977 EPAS3S_pullDriftLongTermTrq 0;
BA_ "Confidence" SG_ 977 EPAS3S_pullDriftCompTrq 0;
BA_ "Confidence" SG_ 977 EPAS3S_learnedSCCMOffset 0;
BA_ "Confidence" SG_ 785 EPAS3S_infoIndex 1;
BA_ "Confidence" SG_ 785 EPAS3S_infoBuildType 0;
BA_ "Confidence" SG_ 785 EPAS3S_infoComponentID 0;
BA_ "Confidence" SG_ 785 EPAS3S_infoPcbaID 0;
BA_ "Confidence" SG_ 785 EPAS3S_infoAssemblyID 0;
BA_ "Confidence" SG_ 785 EPAS3S_infoUsageID 0;
BA_ "Confidence" SG_ 785 EPAS3S_infoApplicationCRC 0;
BA_ "Confidence" SG_ 785 EPAS3S_infoBootUdsProtoVersion 0;
BA_ "Confidence" SG_ 785 EPAS3S_infoBootloaderCRC 0;
BA_ "Confidence" SG_ 785 EPAS3S_infoSubcomponent2 0;
BA_ "Confidence" SG_ 805 ESP_infoIndex 1;
BA_ "Confidence" SG_ 805 ESP_infoBuildType 0;
BA_ "Confidence" SG_ 805 ESP_infoComponentID 0;
BA_ "Confidence" SG_ 805 ESP_infoPcbaID 0;
BA_ "Confidence" SG_ 805 ESP_infoAssemblyID 0;
BA_ "Confidence" SG_ 805 ESP_infoUsageID 0;
BA_ "Confidence" SG_ 805 ESP_infoSubUsageID 0;
BA_ "Confidence" SG_ 805 ESP_infoApplicationCRC 1;
BA_ "Confidence" SG_ 805 ESP_infoVehicleVariant 0;
BA_ "Confidence" SG_ 805 ESP_infoSubcomponent1 0;
BA_ "Confidence" SG_ 805 ESP_infoBootUdsProtoVersion 0;
BA_ "Confidence" SG_ 805 ESP_infoBootloaderCRC 0;
BA_ "Confidence" SG_ 805 ESP_infoVariantCRC 1;
BA_ "Confidence" SG_ 813 IBST_infoIndex 1;
BA_ "Confidence" SG_ 813 IBST_infoBuildType 0;
BA_ "Confidence" SG_ 813 IBST_infoPcbaID 0;
BA_ "Confidence" SG_ 813 IBST_infoAssemblyID 0;
BA_ "Confidence" SG_ 813 IBST_infoUsageID 0;
BA_ "Confidence" SG_ 813 IBST_infoSubUsageID 0;
BA_ "Confidence" SG_ 813 IBST_infoApplicationCRC 0;
BA_ "Confidence" SG_ 813 IBST_infoBootUdsProtoVersion 0;
BA_ "Confidence" SG_ 813 IBST_infoBootloaderCRC 0;
BA_ "Confidence" SG_ 813 IBST_infoVariantCRC 0;
BA_ "Confidence" SG_ 806 PARK_infoIndex 1;
BA_ "Confidence" SG_ 806 PARK_infoBuildType 0;
BA_ "Confidence" SG_ 806 PARK_infoComponentID 0;
BA_ "Confidence" SG_ 806 PARK_infoPcbaID 0;
BA_ "Confidence" SG_ 806 PARK_infoAssemblyID 0;
BA_ "Confidence" SG_ 806 PARK_infoUsageID 0;
BA_ "Confidence" SG_ 806 PARK_infoApplicationCRC 0;
BA_ "Confidence" SG_ 806 PARK_infoBootUdsProtoVersion 0;
BA_ "Confidence" SG_ 806 PARK_infoBootloaderCRC 0;
BA_ "Confidence" SG_ 846 PARK_frontLeftMiddleRawDistData 0;
BA_ "GenSigSNA" SG_ 846 PARK_frontLeftMiddleRawDistData "255";
BA_ "Confidence" SG_ 846 PARK_frontMiddleRawDistData 0;
BA_ "GenSigSNA" SG_ 846 PARK_frontMiddleRawDistData "255";
BA_ "Confidence" SG_ 846 PARK_frontRightMiddleRawDistData 0;
BA_ "GenSigSNA" SG_ 846 PARK_frontRightMiddleRawDistData "255";
BA_ "Confidence" SG_ 846 PARK_pasFrontMiddleCounter 0;
BA_ "Confidence" SG_ 846 PARK_pasFrontMiddleChecksum 0;
BA_ "Confidence" SG_ 926 PARK_rightSideFrontRawDistData 0;
BA_ "GenSigSNA" SG_ 926 PARK_rightSideFrontRawDistData "255";
BA_ "Confidence" SG_ 926 PARK_rightSideRearRawDistData 0;
BA_ "GenSigSNA" SG_ 926 PARK_rightSideRearRawDistData "255";
BA_ "Confidence" SG_ 926 PARK_leftSideFrontRawDistData 0;
BA_ "GenSigSNA" SG_ 926 PARK_leftSideFrontRawDistData "255";
BA_ "Confidence" SG_ 926 PARK_leftSideRearRawDistData 0;
BA_ "GenSigSNA" SG_ 926 PARK_leftSideRearRawDistData "255";
BA_ "Confidence" SG_ 926 PARK_pasSidesCounter 0;
BA_ "Confidence" SG_ 926 PARK_pasSidesChecksum 0;
VAL_ 1020 APP_decisionTemperature 0 "UNKNOWN" ;
VAL_ 1020 APP_pascalTemperature 0 "UNKNOWN" ;
VAL_ 1020 APP_parkerATemperature 0 "UNKNOWN" ;
VAL_ 1020 APP_parkerBTemperature 0 "UNKNOWN" ;
VAL_ 1020 APP_pascalExtTemperature 0 "UNKNOWN" ;
VAL_ 1020 APP_parkerExtTemperature 0 "UNKNOWN" ;
VAL_ 1020 APP_pascalHeaterDecision 1 "ON" 0 "OFF" ;
VAL_ 1018 APP_mainCameraLUX 255 "SNA" 254 "SATURATED" ;
VAL_ 1018 APP_narrowCameraLUX 255 "SNA" 254 "SATURATED" ;
VAL_ 1018 APP_fisheyeCameraLUX 255 "SNA" 254 "SATURATED" ;
VAL_ 1018 APP_lRepeatCameraLUX 255 "SNA" 254 "SATURATED" ;
VAL_ 1018 APP_rRepeatCameraLUX 255 "SNA" 254 "SATURATED" ;
VAL_ 1018 APP_lPillarCameraLUX 255 "SNA" 254 "SATURATED" ;
VAL_ 1018 APP_rPillarCameraLUX 255 "SNA" 254 "SATURATED" ;
VAL_ 1018 APP_backupCameraLUX 255 "SNA" 254 "SATURATED" ;
VAL_ 843 APP_frontLeftParkAssist 255 "SNA" ;
VAL_ 843 APP_frontLeftMiddleParkAssist 255 "SNA" ;
VAL_ 843 APP_frontMiddleParkAssist 255 "SNA" ;
VAL_ 843 APP_frontRightMiddleParkAssist 255 "SNA" ;
VAL_ 843 APP_frontRightParkAssist 255 "SNA" ;
VAL_ 843 APP_parkAssistStatus 3 "SNA" 2 "TEMPORARY_FAILURE" 1 "ENABLED" 0 "DISABLED" ;
VAL_ 1353 APP_infoIndex 3 "AP_BOOT_COUNT" 2 "AP_GITHASH" 1 "FW_GITHASH" 0 "AP_BUILD_TYPE" ;
VAL_ 1353 APP_buildType 3 "AP_BUILDTYPE_REPO" 1 "AP_BUILDTYPE_LOCAL" 0 "AP_BUILDTYPE_SIGNED" ;
VAL_ 907 APP_rearLeftParkAssist 255 "SNA" ;
VAL_ 907 APP_rearLeftMiddleParkAssist 255 "SNA" ;
VAL_ 907 APP_rearMiddleParkAssist 255 "SNA" ;
VAL_ 907 APP_rearRightMiddleParkAssist 255 "SNA" ;
VAL_ 907 APP_rearRightParkAssist 255 "SNA" ;
VAL_ 605 APP_tcFeatureState 3 "TC_ACTIVE" 2 "TC_AVAILABLE" 1 "TC_UNAVAILABLE" 0 "TC_DISABLED" ;
VAL_ 605 APP_tcStateMachine 6 "TCSM_CONTINUING" 5 "TCSM_STOPPED" 4 "TCSM_STOPPING" 3 "TCSM_WARNING" 2 "TCSM_AWARE" 1 "TCSM_STANDBY" 0 "TCSM_DISABLED" ;
VAL_ 605 APP_tcControlSource 3 "TC_SOURCE_MAP_AND_VISION" 2 "TC_SOURCE_VISION" 1 "TC_SOURCE_MAP" 0 "TC_SOURCE_NONE" ;
VAL_ 605 APP_tcControlType 22 "TC_TYPE_T_ARM" 21 "TC_TYPE_BEV_JUNCTION" 20 "TC_TYPE_T_IMPLICIT_BY_GEOM" 19 "TC_TYPE_T_IMPLICIT_BY_NAME" 18 "TC_TYPE_T_IMPLICIT" 17 "TC_TYPE_NO_STOP" 16 "TC_TYPE_BIKE_MERGE_FROM_RIGHT" 15 "TC_TYPE_BIKE_MERGE_FROM_LEFT" 14 "TC_TYPE_ALL_WAY_STOP_SIGN" 13 "TC_TYPE_TRAFFIC_RULE" 12 "TC_TYPE_SPEED_HUMP" 11 "TC_TYPE_SPEED_BUMP" 10 "TC_TYPE_RAMP_METER" 9 "TC_TYPE_PEDESTRIAN_CROSSING" 8 "TC_TYPE_SUICIDE_LEFT" 7 "TC_TYPE_KEEP_CLEAR_EXIT" 6 "TC_TYPE_KEEP_CLEAR_ENTER" 5 "TC_TYPE_CROSSWALK" 4 "TC_TYPE_YIELD" 3 "TC_TYPE_TRAFFIC_LIGHT" 2 "TC_TYPE_STOP_SIGN" 1 "TC_TYPE_UNKNOWN" 0 "TC_TYPE_INVALID" ;
VAL_ 605 APP_tcControlDistance 255 "SNA" ;
VAL_ 605 APP_tcControlLightState 6 "TC_LIGHTSTATE_OTHER" 5 "TC_LIGHTSTAET_WHITE" 4 "TC_LIGHTSTATE_OFF" 3 "TC_LIGHTSTATE_YELLOW" 2 "TC_LIGHTSTATE_GREEN" 1 "TC_LIGHTSTATE_RED" 0 "TC_LIGHTSTATE_NONE" ;
VAL_ 605 APP_tcContinuationReason 13 "TC_CONTINUE_CONTROL_UNAVAILABLE" 12 "TC_CONTINUE_SUMMON_TIMEOUT" 11 "TC_CONTINUE_CLEAR_TO_GO" 10 "TC_CONTINUE_WARNING_TIMEOUT" 9 "TC_CONTINUE_INVALID_MAP_OR_VISION_CONTROL" 8 "TC_CONTINUE_PASSED_STOP" 7 "TC_CONTINUE_ASSUMED_DRIVER_STOPPED" 6 "TC_CONTINUE_AP_ACTIVATED_ON_HARD_STOP" 5 "TC_CONTINUE_VISION_SIGNALS" 4 "TC_CONTINUE_REQUIRED_DECEL_TOO_HIGH" 3 "TC_CONTINUE_USER_INPUT_ON_RED" 2 "TC_CONTINUE_USER_INPUT_ON_GREEN" 1 "TC_CONTINUE_GREEN_LIGHT_WITH_CIPV" 0 "TC_CONTINUE_NONE" ;
VAL_ 605 APP_tcConfirmationType 2 "TC_CONFIRM_PEDAL" 1 "TC_CONFIRM_STALK" 0 "TC_CONFIRM_NONE" ;
VAL_ 605 APP_tcWarningSuppressionReason 18 "TC_WARNING_SUPPRESS_TOO_FAR_FROM_PREDICTED_JUNCTION" 17 "TC_WARNING_SUPPRESS_NOT_SUPPORTED_BY_MEASUREMENTS" 16 "TC_WARNING_SUPPRESS_NO_ASSOCIATED_VISION_LINE" 15 "TC_WARNING_SUPPRESS_AMBIGUOUS_VISION_TYPE" 14 "TC_WARNING_SUPPRESS_CIPV_DID_NOT_STOP" 13 "TC_WARNING_SUPPRESS_STALE_SIGN_DETECTION" 12 "TC_WARNING_SUPPRESS_WRONG_MAP_TYPE" 11 "TC_WARNING_SUPPRESS_LIGHT_UNASSOCIATED" 10 "TC_WARNING_SUPPRESS_CIPV_CONTINUING" 9 "TC_WARNING_SUPPRESS_PEDAL_OVERRIDE" 8 "TC_WARNING_SUPPRESS_LOCALIZATION_DEGRADED" 7 "TC_WARNING_SUPPRESS_HARD_TURN" 6 "TC_WARNING_SUPPRESS_ASSUMED_YELLOW" 5 "TC_WARNING_SUPPRESS_DRIVER_SLOWING_DOWN" 4 "TC_WARNING_SUPPRESS_BELOW_MIN_SPEED" 3 "TC_WARNING_SUPPRESS_SLOWDOWN_PLANNED" 2 "TC_WARNING_SUPPRESS_INSUFFICIENT_DATA" 1 "TC_WARNING_SUPPRESS_FEATURE_DISABLED" 0 "TC_WARNING_SUPPRESS_NONE" ;
VAL_ 605 APP_tcUnavailableReason 9 "AP_UNAVAILBLE_SUN_GLARE_ON_ROAD_RESTRICTED" 8 "AP_UNAVAILBLE_CAMERA_BLINDED_ON_ROAD_RESTRICTED" 7 "AP_UNAVAILBLE_GPS_DEGRADED" 6 "AP_UNAVAILBLE_ROAD_ESTIMATOR_UNHEALTHY" 5 "AP_UNAVAILBLE_SUN_GLARE" 4 "AP_UNAVAILBLE_CAMERA_BLINDED" 3 "AP_UNAVAILBLE_ROAD_CLASS" 2 "AP_UNAVAILBLE_LOST_MAP_LOCALIZATION" 1 "AP_UNAVAILBLE_MCU_DISABLED" 0 "AP_UNAVAILBLE_NONE" ;
VAL_ 859 APP_visionOcsStateRaw 3 "ADULT" 2 "CHILD" 1 "EMPTY" 0 "UNKNOWN" ;
VAL_ 859 APP_visionOcsEmptyProbRaw 255 "SNA" ;
VAL_ 859 APP_visionOcsChildProbRaw 255 "SNA" ;
VAL_ 859 APP_visionOcsAdultProbRaw 255 "SNA" ;
VAL_ 859 APP_visionOcsFrontPasClsVisionSt 3 "ADULT" 2 "CHILD" 1 "EMPTY" 0 "UNKNOWN" ;
VAL_ 637 APS_eacAllow 3 "APS_EAC_SNA" 2 "APS_EAC_RESERVED" 1 "APS_EAC_ALLOW" 0 "APS_EAC_INHIBIT" ;
VAL_ 992 APS_A_lowPowerRequest 5 "APS_LOW_POWER_COLD_RESET" 4 "APS_LOW_POWER_SOC_WARM_RESET" 3 "APS_LOW_POWER_AP_WARM_RESET" 2 "APS_LOW_POWER_OFF" 1 "APS_LOW_POWER_SUSPEND" 0 "APS_LOW_POWER_NONE" ;
VAL_ 992 APS_A_lowPowerRequestor 10 "APS_LOW_POWER_REQ_COUNT" 9 "APS_LOW_POWER_REQ_SGK_PGOOD_IRQ" 8 "APS_LOW_POWER_REQ_SGK_CONSOLE" 7 "APS_LOW_POWER_REQ_SGK_SLEEP" 6 "APS_LOW_POWER_REQ_SGK_UDS" 5 "APS_LOW_POWER_REQ_SGK_BRIDGE" 4 "APS_LOW_POWER_REQ_SGK_FM" 3 "APS_LOW_POWER_REQ_SGK_POWER" 2 "APS_LOW_POWER_REQ_AP_MAILBOX" 1 "APS_LOW_POWER_REQ_AP_ATF" 0 "APS_LOW_POWER_REQ_NONE" ;
VAL_ 992 APS_B_lowPowerRequest 5 "APS_LOW_POWER_COLD_RESET" 4 "APS_LOW_POWER_SOC_WARM_RESET" 3 "APS_LOW_POWER_AP_WARM_RESET" 2 "APS_LOW_POWER_OFF" 1 "APS_LOW_POWER_SUSPEND" 0 "APS_LOW_POWER_NONE" ;
VAL_ 992 APS_B_lowPowerRequestor 10 "APS_LOW_POWER_REQ_COUNT" 9 "APS_LOW_POWER_REQ_SGK_PGOOD_IRQ" 8 "APS_LOW_POWER_REQ_SGK_CONSOLE" 7 "APS_LOW_POWER_REQ_SGK_SLEEP" 6 "APS_LOW_POWER_REQ_SGK_UDS" 5 "APS_LOW_POWER_REQ_SGK_BRIDGE" 4 "APS_LOW_POWER_REQ_SGK_FM" 3 "APS_LOW_POWER_REQ_SGK_POWER" 2 "APS_LOW_POWER_REQ_AP_MAILBOX" 1 "APS_LOW_POWER_REQ_AP_ATF" 0 "APS_LOW_POWER_REQ_NONE" ;
VAL_ 1510 APS_A_cam12v0Voltage 4095 "SNA" ;
VAL_ 1510 APS_B_cam12v0Voltage 4095 "SNA" ;
VAL_ 1510 APS_A_turboMaxTemperature -128 "SNA" ;
VAL_ 1510 APS_A_turboProbeType 63 "SNA" ;
VAL_ 1510 APS_B_turboMaxTemperature -128 "SNA" ;
VAL_ 1510 APS_B_turboProbeType 63 "SNA" ;
VAL_ 1497 DAS_carLogMultiplexer 3 "PROFILER" 2 "FCM" 1 "RADAR" 0 "FEATURE_STATE" ;
VAL_ 1497 DAS_radarTarget5_dx 0 "NO_TARGET" ;
VAL_ 1497 DAS_radarTarget1_dx 0 "NO_TARGET" ;
VAL_ 1497 DAS_radarTarget1_VxRel 0 "NO_TARGET" ;
VAL_ 1497 DAS_associated_rad_object 3 "ACC1" 2 "ACC5" 1 "OTHER" 0 "NONE" ;
VAL_ 1497 DAS_LC_handsOnReason 63 "VISUAL_DCAS_BOUNDARY_CONDITION" 62 "VISUAL_DCAS_STRICT_PHONE_USE" 61 "VISUAL_DCAS_EYES_ON_REQUEST_FAST" 60 "VISUAL_EYE_GAZE_AVERSION" 59 "VISUAL_NO_EYE_GAZE_DEVIATION" 58 "CHIME1_DCAS_STRICT_PHONE_USE" 57 "VISUAL_DCAS_EYES_ON_REQUEST" 56 "CHIME1_DCAS_EYES_ON_REQUEST_FAST" 55 "CHIME1_DCAS_EYES_ON_REQUEST" 54 "CHIME1_NO_EYE_GAZE_DEVIATION" 53 "VISUAL_ATTN_MONITORING_UNAVAILABLE" 52 "VISUAL_DRIVER_HANDS_NOT_READY" 51 "VISUAL_TIMEOUT_SUNGLASSES" 50 "CHIME1_REACHING_AFTER_AP_ACTIVATION" 49 "VISUAL_DRIVER_POSSIBLY_DISTRACTED" 48 "VISUAL_DRIVER_LOW_ATTENTION_SCORE" 47 "VISUAL_DRIVER_LOSS_OF_ATTENTION" 46 "VISUAL_VRU_FAILSAFE" 45 "VISUAL_VRU_IN_DRIVE_SPACE" 44 "CHIME1_UPCOMING_TRAFFIC_CONTROL" 43 "CHIME1_HANDS_OFF_AFTER_AP_ACTIVATION" 42 "VISUAL_UPCOMING_TRAFFIC_CONTROL" 41 "CHIME1_DISTRACTED_AFTER_AP_ACTIVATION" 40 "VISUAL_DRIVER_STATE_UNKNOWN" 39 "VISUAL_TIMEOUT_DRIVER_NOT_LIVELY" 38 "VISUAL_TIMEOUT_TORQUE_OFFSET_UNCALIBRATED" 37 "CHIME1_REFERENCE_LATERAL_ERROR" 36 "CHIME1_STREET_CAR" 35 "CHIME1_SEALED_MERGE_WARNING" 34 "CHIME1_CAUTION_LIGHTS" 33 "CHIME1_CAPTIVE_EXIT" 32 "CHIME1_CRITICAL_TRAFFIC_CONTROL" 31 "VISUAL_POOR_VISIBILITY" 30 "CHIME1_DRIVER_DISTRACTED" 29 "DEFEAT_DEVICE_DETECTED" 28 "VISUAL_TRAFFIC_CONTROLS" 27 "CHIME1_EXTREME_WEATHER" 26 "VISUAL_POOR_WEATHER" 25 "VISUAL_STOP_AND_GO" 24 "VISUAL_TIMEOUT_HOMOLOGATION" 23 "VISUAL_ULC_REQUEST" 22 "CHIME1_TOLL_BOOTH" 21 "CHIME1_STATIONARY_RADAR" 20 "CHIME1_DRIVABLE_SPACE_VIOLATION" 19 "CHIME1_RE_DEGRADED_MEASUREMENTS" 18 "CHIME1_NO_LINES" 17 "VISUAL_ALC" 16 "VISUAL_LATERAL_ACCELERATION" 15 "VISUAL_TIMEOUT_ACCELERATOR" 14 "VISUAL_TIMEOUT_RESTRICTED" 13 "VISUAL_TIMEOUT_NO_CIPV" 12 "VISUAL_TIMEOUT_CIPV" 11 "VISUAL_TIMEOUT_CUTOUT_CIPV" 10 "VISUAL_TIMEOUT_CONSTRUCTION" 9 "VISUAL_TIMEOUT_LOW_SPEED" 8 "VISUAL_TIMEOUT_MED_SPEED" 7 "VISUAL_TIMEOUT_HI_SPEED" 6 "VISUAL_TIMEOUT_LONG_TERM" 5 "VISUAL_DRIVER_NOT_PRESENT" 4 "VISUAL_FUSION_MODEL" 3 "VISUAL_FUSION_NAV" 2 "CHIME1_CONSTRUCTION" 1 "CHIME1_ANGLE_SATURATION" 0 "LC_HANDS_ON_REASON_NONE" ;
VAL_ 1497 DAS_ACC_camStatus 3 "ACC_CAM_STATUS_FAULT" 2 "ACC_CAM_STATUS_SQUINTING" 1 "ACC_CAM_STATUS_BLIND" 0 "ACC_CAM_STATUS_HEALTHY" ;
VAL_ 1497 DAS_aeb_not_activating_reason 22 "LCM_AEB_SENSORS_DO_NOT_AGREE" 21 "LCM_AEB_NOT_RADAR_CIPV" 20 "LCM_AEB_LANE_ASSIGNMENT_AGE" 19 "LCM_AEB_COLLISION_COURSE_TIME" 18 "LCM_AEB_TRACK_CONSISTENCY" 17 "LCM_AEB_DRIVABLE_SPACE" 16 "LCM_AEB_PATH_OVERLAP" 15 "LCM_AEB_RAD_NOT_ASSOCIATED" 14 "LCM_AEB_CAM_NOT_ASSOCIATED" 13 "LCM_AEB_CAMERA_CROSS_CHECK" 12 "LCM_AEB_YOUNG_TRACK" 11 "LCM_AEB_OTHER" 10 "LCM_AEB_ACTIVE" 9 "LCM_AEB_OVERRIDE" 8 "LCM_AEB_DELAYED_EVADING_DISTANCE" 7 "LCM_AEB_DELAYED_REQUIRED_ACCELERATION" 6 "LCM_AEB_CURRENT_REQUIRED_ACCELERATION" 5 "LCM_AEB_COLLISION_OVERLAP_RATIO" 4 "LCM_AEB_RELATIVE_VELOCITY" 3 "LCM_AEB_ABSOLUTE_ACCELERATION" 2 "LCM_AEB_NO_COLLISION_OBJECT" 1 "LCM_AEB_UNAVAILABLE" 0 "LCM_AEB_FAULT" ;
VAL_ 1497 DAS_handsOnDetected 2 "HANDS_ON_DETECTED" 1 "HANDS_ON_NOT_DETECTED" 0 "HANDS_ON_SNA" ;
VAL_ 1497 DAS_driveOnNavUnavailableReason 25 "DON_BLINKER_FAULTED" 24 "DON_UNAVAILABLE_AUDIO" 23 "DON_SCENE_TAG_SUN_GLARE" 22 "DON_SCENE_TAG_SEVERE_WEATHER" 21 "DON_SCENE_TAG_LENS_FLARE" 20 "DON_SCENE_TAG_FULLY_BLOCKED" 19 "DON_SCENE_TAG_FOG" 18 "DON_SCENE_TAG_BLURRY" 17 "DON_SCENE_TAG_BAD_CAMERA" 16 "DON_NAV_ROUTE_NOT_ACTIVE" 15 "DON_FEATURE_NOT_ENABLED" 14 "DON_AUTOPILOT_UNAVAILABLE" 13 "DON_INCOMPATIBLE_WAY" 12 "DON_HIGH_CURVATURE" 11 "DON_TOLLBOOTH_DETECTED" 10 "DON_CONSTRUCTION_DETECTED" 9 "DON_AUTO_WIPER_ACTIVE" 8 "DON_IMPLAUSIBLE_MAP_DATA" 7 "DON_GPS_DEGRADED" 6 "DON_ULTRASONICS_INVALID" 5 "DON_EDGE_LOCALIZATION_FAILED" 4 "DON_ROUTE_DOWNLOAD_FAILED" 3 "DON_UNAVAILABLE_CAMERA_BLOCKED" 2 "DON_CAMERA_UNAVAILABLE" 1 "DON_INVALID_NAV_GOAL" 0 "DON_UNAVAILABLE_NONE" ;
VAL_ 1497 DAS_accUnavailableReason 76 "ACC_UNAVAILABLE_REASON_SEATBELT_UNBUCKLED" 75 "ACC_UNAVAILABLE_REASON_DOOR_OPEN" 74 "ACC_UNAVAILABLE_REASON_FRUNK_OPEN" 73 "ACC_UNAVAILABLE_REASON_TRUNK_OPEN" 72 "ACC_UNAVAILABLE_REASON_OFF_ROAD_MODE_ACTIVE" 71 "ACC_UNAVAILABLE_REASON_SUPPRESS_FOR_RECENT_SCROLL_WHEEL_INTERACTION" 70 "ACC_UNAVAILABLE_REASON_SUPPRESS_FOR_RECENT_AUTOPARK_ACTIVATION" 69 "ACC_UNAVAILABLE_REASON_USER_SETTINGS_NOT_SUPPORTED" 68 "ACC_UNAVAILABLE_REASON_AUTOSTEER_INACTIVE_FOR_SINGLE_CLICK" 67 "ACC_UNAVAILABLE_REASON_AUTOSTEER_UNAVAILABLE_FOR_SINGLE_CLICK" 66 "ACC_UNAVAILABLE_REASON_TASK_FLOW_TRACE_TIMEOUT_SLAM" 65 "ACC_UNAVAILABLE_REASON_TASK_FLOW_TRACE_TIMEOUT_LOCALIZATION" 64 "ACC_UNAVAILABLE_REASON_TASK_FLOW_TRACE_TIMEOUT_STATIC_WORLD" 63 "ACC_UNAVAILABLE_REASON_TASK_FLOW_TRACE_TIMEOUT_DYNAMIC_WORLD" 62 "ACC_UNAVAILABLE_REASON_TASK_FLOW_TRACE_TIMEOUT_UNKNOWN" 61 "ACC_UNAVAILABLE_REASON_EXTENDED_COMPUTE_INACTIVE_PCIE_LINK_HEALTH" 60 "ACC_UNAVAILABLE_REASON_EXTENDED_COMPUTE_INACTIVE_ETHERNET_LINK_HEALTH" 59 "ACC_UNAVAILABLE_REASON_EXTENDED_COMPUTE_INACTIVE_OTHER_SOC_HEALTH_CRITICAL" 58 "ACC_UNAVAILABLE_REASON_EXTENDED_COMPUTE_INACTIVE_OTHER_SOC_HEALTH_UNKNOWN" 57 "ACC_UNAVAILABLE_REASON_AHB_MANUAL_OVERRIDE" 56 "ACC_UNAVAILABLE_REASON_EXTENDED_COMPUTE_INACTIVE" 55 "ACC_UNAVAILABLE_REASON_DRIVER_NOT_PRESENT" 54 "ACC_UNAVAILABLE_REASON_LOW_ODOMETRY" 53 "ACC_UNAVAILABLE_REASON_PERCEPTION_HEALTH_STALE" 52 "ACC_UNAVAILABLE_REASON_PERCEPTION_HEALTH_POST_PROCESSING" 51 "ACC_UNAVAILABLE_REASON_RECENT_USER_CANCELLATION" 50 "ACC_UNAVAILABLE_REASON_CITY_STREETS_REF_TOO_SHORT" 49 "ACC_UNAVAILABLE_REASON_INVALID_BEHAVIOR" 48 "ACC_UNAVAILABLE_REASON_RECENT_GEAR_SHIFT" 47 "ACC_UNAVAILABLE_REASON_IBOOSTER_MIA" 46 "ACC_UNAVAILABLE_INTEGRATOR_HEALTH_CRITICAL" 45 "ACC_UNAVAILABLE_REASON_UNKNOWN" 44 "ACC_UNAVAILABLE_REASON_RADAR_VERSION_MISMATCH" 43 "ACC_UNAVAILABLE_REASON_AP_NOT_CONFIGURED" 42 "ACC_UNAVAILABLE_REASON_INVALID_VEHICLE_SPEED" 41 "ACC_UNAVAILABLE_REASON_INVALID_DI_PEDAL_POS" 40 "ACC_UNAVAILABLE_REASON_W048_FEATURES_DISABLED" 39 "ACC_UNAVAILABLE_REASON_FAILED_AUTOSTEER_ACTIVATION" 38 "ACC_UNAVAILABLE_REASON_AEB_ACTIVE" 37 "ACC_UNAVAILABLE_REASON_AVAILABILITY_CHECK_HYSTERESIS" 36 "ACC_UNAVAILABLE_REASON_SONIC_OBSTACLE_DETECTED" 35 "ACC_UNAVAILABLE_REASON_TRACKED_OBSTACLE_DETECTED" 34 "ACC_UNAVAILABLE_REASON_STEERING_WHEEL_ANGLE" 33 "ACC_UNAVAILABLE_REASON_ROAD_CLASS" 32 "ACC_UNAVAILABLE_REASON_BELOW_MIN_SPEED" 31 "ACC_UNAVAILABLE_REASON_PEDESTRIAN_PRESENT_OR_NO_VEHICLE" 30 "ACC_UNAVAILABLE_REASON_BELOW_MAX_UNAVAILABLE_SPEED" 29 "ACC_UNAVAILABLE_REASON_ESP_PARTY_MIA" 28 "ACC_UNAVAILABLE_REASON_EPAS_PARTY_MIA" 27 "ACC_UNAVAILABLE_REASON_DI_PARTY_MIA" 26 "ACC_UNAVAILABLE_REASON_ECU_THERMAL_ISSUE" 25 "ACC_UNAVAILABLE_REASON_CAMERA_FAILSAFES" 24 "ACC_UNAVAILABLE_REASON_ESP_MIA" 23 "ACC_UNAVAILABLE_REASON_EPAS_MIA" 22 "ACC_UNAVAILABLE_REASON_GTW_MIA" 21 "ACC_UNAVAILABLE_REASON_DI_MIA" 20 "ACC_UNAVAILABLE_REASON_NOT_IN_DRIVE" 19 "ACC_UNAVAILABLE_REASON_CONTROLLER_INDETERMINATE" 18 "ACC_UNAVAILABLE_REASON_CONTROLLER_REFERENCE_TOO_SHORT" 17 "ACC_UNAVAILABLE_REASON_CONTROLLER_BAD_UPDATE" 16 "ACC_UNAVAILABLE_REASON_CONTROLLER_STALE_LOCALIZATION" 15 "ACC_UNAVAILABLE_REASON_CONTROLLER_STALE_REFERENCE" 14 "ACC_UNAVAILABLE_REASON_CONTROLLER_REFERENCE_UNHEALTHY" 13 "ACC_UNAVAILABLE_REASON_CONTROLLER_SOLVER_UNHEALTHY" 12 "ACC_UNAVAILABLE_REASON_CONTROLLER_NOT_ALLOWED" 11 "ACC_UNAVAILABLE_REASON_CAMERA_CALIBRATION" 10 "ACC_UNAVAILABLE_REASON_CAMERA_PITCH" 9 "ACC_UNAVAILABLE_REASON_CAMERA_BLOCKED" 8 "ACC_UNAVAILABLE_REASON_RADAR_MIA" 7 "ACC_UNAVAILABLE_REASON_RADAR_FAULT" 6 "ACC_UNAVAILABLE_REASON_RADAR_BLIND" 5 "ACC_UNAVAILABLE_REASON_PERCEPTION_HEALTH_VISION" 4 "ACC_UNAVAILABLE_REASON_PERCEPTION_HEALTH_RADAR" 3 "ACC_UNAVAILABLE_REASON_DI_CRUISE_STATE_CRITICAL" 2 "ACC_UNAVAILABLE_REASON_AUTOPARK_STATE" 1 "ACC_UNAVAILABLE_REASON_SYSTEM_HEALTH_CRITICAL" 0 "ACC_UNAVAILABLE_REASON_NONE" ;
VAL_ 1497 DAS_pmmNotActivatingReason 24 "PMM_NOT_ACTIVATING_OTHER" 23 "PMM_NOT_ACTIVATING_DI_STATUS" 22 "PMM_NOT_ACTIVATING_HARDWARE_NOT_SUPPORTED" 21 "PMM_NOT_ACTIVATING_DYNAMIC_BARRIER" 20 "PMM_NOT_ACTIVATING_TRAILER_MODE" 19 "PMM_NOT_ACTIVATING_DROPPED_CIPV" 18 "PMM_NOT_ACTIVATING_SPEED_DERIVATIVE" 17 "PMM_NOT_ACTIVATING_SCENE_TAG" 16 "PMM_NOT_ACTIVATING_MODE" 15 "PMM_NOT_ACTIVATING_SPEED_PROFILE" 14 "PMM_NOT_ACTIVATING_INSEVERE_CIPV" 13 "PMM_NOT_ACTIVATING_WHEEL_ACCELERATION" 12 "PMM_NOT_ACTIVATING_ULTRASONIC_VELOCITY" 11 "PMM_NOT_ACTIVATING_ULTRASONIC_DISTANCE" 10 "PMM_NOT_ACTIVATING_USER_DISABLED" 9 "PMM_NOT_ACTIVATING_ROAD" 8 "PMM_NOT_ACTIVATING_SDI_HEALTH" 7 "PMM_NOT_ACTIVATING_VEHICLE_SPEED" 6 "PMM_NOT_ACTIVATING_TRACK_MODE" 5 "PMM_NOT_ACTIVATING_GEAR" 4 "PMM_NOT_ACTIVATING_PEDAL_RATE" 3 "PMM_NOT_ACTIVATING_PEDAL_POS" 2 "PMM_NOT_ACTIVATING_OBSTACLE_GRID" 1 "PMM_NOT_ACTIVATING_APP_FEATURES_NOT_AVAILABLE" 0 "PMM_NOT_ACTIVATING_NONE" ;
VAL_ 1497 DAS_desiredTarget_dx 255 "SNA" ;
VAL_ 1497 DAS_radarTarget2_dx 0 "NO_TARGET" ;
VAL_ 1497 DAS_radarTarget3_dx 0 "NO_TARGET" ;
VAL_ 1497 DAS_radarTarget4_dx 0 "NO_TARGET" ;
VAL_ 1497 DAS_closestInLaneTargetDx 0 "NO_TARGET" ;
VAL_ 1497 DAS_secondInLaneTargetDx 0 "NO_TARGET" ;
VAL_ 1497 DAS_closestLeftLaneTargetDx 0 "NO_TARGET" ;
VAL_ 1497 DAS_closestRightLaneTargetDx 0 "NO_TARGET" ;
VAL_ 1497 DAS_closestInLaneTargetVxRel 0 "NO_TARGET" ;
VAL_ 1337 DAS_infoIndex 255 "END" 24 "EYEQ_FFS" 23 "EYEQ_APP" 20 "UDS_PROTOCOL_BOOTCRC" 19 "VERSION_DEPRECATED" 18 "BOOTLOADER_GITHASH" 17 "APP_GITHASH" 16 "EYEQ_BOOT" 15 "BOOTLOADER_CRC" 14 "BOOTLOADER_SVN" 13 "APP_CRC" 11 "PCBAID_ASSYID_USAGEID" 10 "BUILD_HWID_COMPONENTID" 9 "DEPRECATED_9" 8 "DEPRECATED_8" 7 "DEPRECATED_7" 6 "DEPRECATED_6" 5 "DEPRECATED_5" 4 "DEPRECATED_4" 3 "DEPRECATED_3" 2 "DEPRECATED_2" 1 "DEPRECATED_1" 0 "DEPRECATED_0" ;
VAL_ 1337 DAS_infoBuildType 4 "INFO_MFG_BUILD" 3 "INFO_TRACEABLE_CI_BUILD" 2 "INFO_LOCAL_BUILD" 1 "INFO_PLATFORM_BUILD" 0 "INFO_UNKNOWN_BUILD" ;
VAL_ 569 DAS_leftLineUsage 3 "BLACKLISTED" 2 "FUSED" 1 "AVAILABLE" 0 "REJECTED_UNAVAILABLE" ;
VAL_ 569 DAS_rightLineUsage 3 "BLACKLISTED" 2 "FUSED" 1 "AVAILABLE" 0 "REJECTED_UNAVAILABLE" ;
VAL_ 569 DAS_leftFork 3 "FORK_UNAVAILABLE" 2 "FORK_SELECTED" 1 "FORK_AVAILABLE" 0 "FORK_NONE" ;
VAL_ 569 DAS_rightFork 3 "FORK_UNAVAILABLE" 2 "FORK_SELECTED" 1 "FORK_AVAILABLE" 0 "FORK_NONE" ;
VAL_ 921 DAS_autopilotState 15 "SNA" 14 "FAULT" 9 "ABORTED" 8 "ABORTING" 6 "ACTIVE_FSD" 5 "ACTIVE_NAV" 4 "ACTIVE_RESTRICTED" 3 "ACTIVE_NOMINAL" 2 "AVAILABLE" 1 "UNAVAILABLE" 0 "DISABLED" ;
VAL_ 921 DAS_blindSpotRearLeft 3 "SNA" 2 "WARNING_LEVEL_2" 1 "WARNING_LEVEL_1" 0 "NO_WARNING" ;
VAL_ 921 DAS_blindSpotRearRight 3 "SNA" 2 "WARNING_LEVEL_2" 1 "WARNING_LEVEL_1" 0 "NO_WARNING" ;
VAL_ 921 DAS_fusedSpeedLimit 31 "NONE" 0 "UNKNOWN_SNA" ;
VAL_ 921 DAS_suppressSpeedWarning 1 "Suppress_Speed_Warning" 0 "Do_Not_Suppress" ;
VAL_ 921 DAS_visionOnlySpeedLimit 31 "NONE" 0 "UNKNOWN_SNA" ;
VAL_ 921 DAS_heaterState 1 "HEATER_ON" 0 "HEATER_OFF_SNA" ;
VAL_ 921 DAS_forwardCollisionWarning 3 "SNA" 1 "FORWARD_COLLISION_WARNING" 0 "NONE" ;
VAL_ 921 DAS_autoparkReady 1 "AUTOPARK_READY" 0 "AUTOPARK_UNAVAILABLE" ;
VAL_ 921 DAS_lssState 7 "LSS_STATE_OFF" 6 "LSS_STATE_ABORT" 5 "LSS_STATE_BLINDSPOT" 4 "LSS_STATE_MONITOR" 3 "LSS_STATE_ELK" 2 "LSS_STATE_LKA" 1 "LSS_STATE_LDW" 0 "LSS_STATE_FAULT" ;
VAL_ 921 DAS_sideCollisionAvoid 3 "SNA" 2 "AVOID_RIGHT" 1 "AVOID_LEFT" 0 "NONE" ;
VAL_ 921 DAS_sideCollisionWarning 3 "WARN_LEFT_RIGHT" 2 "WARN_RIGHT" 1 "WARN_LEFT" 0 "NONE" ;
VAL_ 921 DAS_sideCollisionInhibit 1 "INHIBIT" 0 "NO_INHIBIT" ;
VAL_ 921 DAS_laneDepartureWarning 5 "SNA" 4 "RIGHT_WARNING_SEVERE" 3 "LEFT_WARNING_SEVERE" 2 "RIGHT_WARNING" 1 "LEFT_WARNING" 0 "NONE" ;
VAL_ 921 DAS_fleetSpeedState 3 "FLEETSPEED_HOLD" 2 "FLEETSPEED_ACTIVE" 1 "FLEETSPEED_AVAILABLE" 0 "FLEETSPEED_UNAVAILABLE" ;
VAL_ 921 DAS_autopilotHandsOnState 15 "LC_HANDS_ON_SNA" 10 "LC_HANDS_ON_REQD_ESCALATED_CHIME_2" 9 "LC_HANDS_ON_REQD_ESCALATED_CHIME_1" 8 "LC_HANDS_ON_SUSPENDED" 7 "LC_HANDS_ON_REQD_STRUCK_OUT" 6 "LC_HANDS_ON_REQD_SLOWING" 5 "LC_HANDS_ON_REQD_CHIME_2" 4 "LC_HANDS_ON_REQD_CHIME_1" 3 "LC_HANDS_ON_REQD_VISUAL" 2 "LC_HANDS_ON_REQD_NOT_DETECTED" 1 "LC_HANDS_ON_REQD_DETECTED" 0 "LC_HANDS_ON_NOT_REQD" ;
VAL_ 921 DAS_autoLaneChangeState 31 "ALC_SNA" 30 "ALC_ABORT_MISSION_PLAN_INVALID" 29 "ALC_ABORT_TIMEOUT" 28 "ALC_WAITING_HANDS_ON" 27 "ALC_BLOCKED_LANE_TYPE_R" 26 "ALC_BLOCKED_LANE_TYPE_L" 25 "ALC_BLOCKED_VEH_TTC_AND_USS_R" 24 "ALC_BLOCKED_VEH_TTC_R" 23 "ALC_BLOCKED_VEH_TTC_AND_USS_L" 22 "ALC_BLOCKED_VEH_TTC_L" 21 "ALC_UNAVAILABLE_SOLID_LANE_LINE" 20 "ALC_ABORT_OTHER_REASON" 19 "ALC_ABORT_BLINKER_TURNED_OFF" 18 "ALC_ABORT_LC_HEALTH_BAD" 17 "ALC_ABORT_POOR_VIEW_RANGE" 16 "ALC_ABORT_SIDE_OBSTACLE_PRESENT_R" 15 "ALC_ABORT_SIDE_OBSTACLE_PRESENT_L" 14 "ALC_WAITING_FOR_FWD_OBST_TO_PASS_R" 13 "ALC_WAITING_FOR_FWD_OBST_TO_PASS_L" 12 "ALC_WAITING_FOR_SIDE_OBST_TO_PASS_R" 11 "ALC_WAITING_FOR_SIDE_OBST_TO_PASS_L" 10 "ALC_IN_PROGRESS_R" 9 "ALC_IN_PROGRESS_L" 8 "ALC_AVAILABLE_BOTH" 7 "ALC_AVAILABLE_ONLY_R" 6 "ALC_AVAILABLE_ONLY_L" 5 "ALC_UNAVAILABLE_VEHICLE_SPEED" 4 "ALC_UNAVAILABLE_EXITING_HIGHWAY" 3 "ALC_UNAVAILABLE_TP_FOLLOW" 2 "ALC_UNAVAILABLE_SONICS_INVALID" 1 "ALC_UNAVAILABLE_NO_LANES" 0 "ALC_UNAVAILABLE_DISABLED" ;
VAL_ 905 DAS_accSpeedLimit 511 "SNA" 0 "NONE" ;
VAL_ 905 DAS_pmmObstacleSeverity 7 "PMM_SNA" 6 "PMM_ACCEL_LIMIT" 5 "PMM_CRASH_FRONT" 4 "PMM_CRASH_REAR" 3 "PMM_BRAKE_REQUEST" 2 "PMM_IMMINENT_FRONT" 1 "PMM_IMMINENT_REAR" 0 "PMM_NONE" ;
VAL_ 905 DAS_pmmLoggingRequest 1 "TRUE" 0 "FALSE" ;
VAL_ 905 DAS_activationFailureStatus 2 "LC_ACTIVATION_FAILED_2" 1 "LC_ACTIVATION_FAILED_1" 0 "LC_ACTIVATION_IDLE" ;
VAL_ 905 DAS_pmmUltrasonicsFaultReason 4 "PMM_ULTRASONICS_INVALID_MIA" 3 "PMM_ULTRASONICS_BLOCKED_BOTH" 2 "PMM_ULTRASONICS_BLOCKED_REAR" 1 "PMM_ULTRASONICS_BLOCKED_FRONT" 0 "PMM_ULTRASONICS_NO_FAULT" ;
VAL_ 905 DAS_pmmRadarFaultReason 2 "PMM_RADAR_INVALID_MIA" 1 "PMM_RADAR_BLOCKED_FRONT" 0 "PMM_RADAR_NO_FAULT" ;
VAL_ 905 DAS_pmmSysFaultReason 7 "PMM_FAULT_BRAKE_PEDAL_INHIBIT" 6 "PMM_FAULT_ROAD_TYPE" 5 "PMM_FAULT_DISABLED_BY_USER" 4 "PMM_FAULT_STEERING_ANGLE_RATE" 3 "PMM_FAULT_DI_FAULT" 2 "PMM_FAULT_SPEED" 1 "PMM_FAULT_DAS_DISABLED" 0 "PMM_FAULT_NONE" ;
VAL_ 905 DAS_pmmCameraFaultReason 2 "PMM_CAMERA_INVALID_MIA" 1 "PMM_CAMERA_BLOCKED_FRONT" 0 "PMM_CAMERA_NO_FAULT" ;
VAL_ 905 DAS_ACC_report 24 "ACC_REPORT_BEHAVIOR_REPORT" 23 "ACC_REPORT_CAMERA_ONLY" 22 "ACC_REPORT_RADAR_OBJ_FIVE" 21 "ACC_REPORT_CIPV_CUTTING_OUT" 20 "ACC_REPORT_MCVLR_IN_PATH" 19 "ACC_REPORT_MCVLR_DPP" 18 "ACC_REPORT_FLEET_SPEEDS" 17 "ACC_REPORT_TARGET_MCP" 16 "ACC_REPORT_RADAR_OBJ_TWO" 15 "ACC_REPORT_RADAR_OBJ_ONE" 14 "ACC_REPORT_LC_EXTERNAL_STATE_ACTIVE_RESTRICTED" 13 "ACC_REPORT_LC_EXTERNAL_STATE_ABORTED" 12 "ACC_REPORT_LC_EXTERNAL_STATE_ABORTING" 11 "ACC_REPORT_LC_HANDS_ON_REQD_STRUCK_OUT" 10 "ACC_REPORT_CSA" 9 "ACC_REPORT_TARGET_TYPE_FAULT" 8 "ACC_REPORT_TARGET_TYPE_IPSO" 7 "ACC_REPORT_TARGET_TYPE_TRAFFIC_LIGHT" 6 "ACC_REPORT_TARGET_TYPE_STOP_SIGN" 5 "ACC_REPORT_TARGET_CUTIN" 4 "ACC_REPORT_TARGET_MCVR" 3 "ACC_REPORT_TARGET_MCVL" 2 "ACC_REPORT_TARGET_IN_FRONT_OF_CIPV" 1 "ACC_REPORT_TARGET_CIPV" 0 "ACC_REPORT_TARGET_NONE" ;
VAL_ 905 DAS_csaState 3 "CSA_EXTERNAL_STATE_HOLD" 2 "CSA_EXTERNAL_STATE_ENABLE" 1 "CSA_EXTERNAL_STATE_AVAILABLE" 0 "CSA_EXTERNAL_STATE_UNAVAILABLE" ;
VAL_ 905 DAS_radarTelemetry 2 "RADAR_TELEMETRY_URGENT" 1 "RADAR_TELEMETRY_NORMAL" 0 "RADAR_TELEMETRY_IDLE" ;
VAL_ 905 DAS_robState 3 "ROB_STATE_MAPLESS" 2 "ROB_STATE_ACTIVE" 1 "ROB_STATE_MEASURE" 0 "ROB_STATE_INHIBITED" ;
VAL_ 905 DAS_driverInteractionLevel 2 "CONTINUED_DRIVER_NOT_INTERACTING" 1 "DRIVER_NOT_INTERACTING" 0 "DRIVER_INTERACTING" ;
VAL_ 905 DAS_ppOffsetDesiredRamp 128 "PP_NO_OFFSET" ;
VAL_ 905 DAS_longCollisionWarning 15 "FCM_LONG_COLLISION_WARNING_SNA" 12 "FCM_LONG_COLLISION_WARNING_VEHICLE_CIPV2" 11 "FCM_LONG_COLLISION_WARNING_VEHICLE_MCVR2" 10 "FCM_LONG_COLLISION_WARNING_VEHICLE_MCVR" 9 "FCM_LONG_COLLISION_WARNING_VEHICLE_MCVL2" 8 "FCM_LONG_COLLISION_WARNING_VEHICLE_MCVL" 7 "FCM_LONG_COLLISION_WARNING_VEHICLE_CUTIN" 6 "FCM_LONG_COLLISION_WARNING_VEHICLE_CIPV" 5 "FCM_LONG_COLLISION_WARNING_TFL_STOPLINE" 4 "FCM_LONG_COLLISION_WARNING_STOPSIGN_STOPLINE" 3 "FCM_LONG_COLLISION_WARNING_IPSO" 2 "FCM_LONG_COLLISION_WARNING_PEDESTRIAN" 1 "FCM_LONG_COLLISION_WARNING_VEHICLE_UNKNOWN" 0 "FCM_LONG_COLLISION_WARNING_NONE" ;
VAL_ 586 DAS_autosteerVehiclesUsage 3 "BLACKLISTED" 2 "FUSED" 1 "AVAILABLE" 0 "REJECTED_UNAVAILABLE" ;
VAL_ 586 DAS_autosteerHPPUsage 3 "BLACKLISTED" 2 "FUSED" 1 "AVAILABLE" 0 "REJECTED_UNAVAILABLE" ;
VAL_ 586 DAS_autosteerNavigationUsage 3 "BLACKLISTED" 2 "FUSED" 1 "AVAILABLE" 0 "REJECTED_UNAVAILABLE" ;
VAL_ 586 DAS_autosteerModelUsage 3 "BLACKLISTED" 2 "FUSED" 1 "AVAILABLE" 0 "REJECTED_UNAVAILABLE" ;
VAL_ 586 DAS_autosteerBottsDotsUsage 3 "BLACKLISTED" 2 "FUSED" 1 "AVAILABLE" 0 "REJECTED_UNAVAILABLE" ;
VAL_ 586 DAS_offsetSide 3 "OFFSET_BOTH_OBJECTS" 2 "OFFSET_LEFT_OBJECT" 1 "OFFSET_RIGHT_OBJECT" 0 "NO_OFFSET" ;
VAL_ 586 DAS_roadSurfaceType 2 "ROAD_SURFACE_ENHANCED" 1 "ROAD_SURFACE_NORMAL" 0 "ROAD_SURFACE_SNA" ;
VAL_ 586 DAS_autosteerHealthState 5 "HEALTH_FAULT" 4 "HEALTH_ABORTING" 3 "HEALTH_SEVERELY_DEGRADED" 2 "HEALTH_DEGRADED" 1 "HEALTH_NOMINAL" 0 "HEALTH_UNAVAILABLE" ;
VAL_ 586 DAS_lastLinePreferenceReason 15 "NONE" 5 "COUNTRY_DRIVING_SIDE" 4 "AVOID_ONCOMING_LANES" 3 "NAVIGATION_BRANCH" 2 "NEIGHBOR_LANE_PROBABILIY" 1 "AGREEMENT_WITH_NEIGHBOR_LANES" 0 "OTHER_LANE_DISAGREES_WITH_MODEL" ;
VAL_ 586 DAS_plannerState 7 "TP_EXTSTATE_LANECHANGE_ABORT" 6 "TP_EXTSTATE_LANECHANGE_WAIT_FOR_FWD_OBSTACLE" 5 "TP_EXTSTATE_LANECHANGE_WAIT_FOR_SIDE_OBSTACLE" 4 "TP_EXTSTATE_LANECHANGE_IN_PROGRESS" 3 "TP_EXTSTATE_LANECHANGE_REQUESTED" 2 "TP_EXTSTATE_FOLLOW" 1 "TP_EXTSTATE_VL" 0 "TP_EXTSTATE_DISABLED" ;
VAL_ 586 DAS_lastAutosteerAbortReason 36 "UI_ABORT_REASON_AHB_MANUAL_OVERRIDE" 35 "UI_ABORT_REASON_DRIVER_NOT_PRESENT" 34 "UI_ABORT_REASON_USER_OVERRIDE_STRIKEOUT" 33 "UI_ABORT_REASON_SEATBELT_UNBUCKLED" 32 "UI_ABORT_REASON_AEB" 31 "UI_ABORT_REASON_NO_ABORT" 30 "UI_ABORT_REASON_CAMERA_FAILSAFES" 29 "UI_ABORT_REASON_ACC_CANCEL" 28 "UI_ABORT_REASON_EPAS_ERROR_CODE" 27 "UI_ABORT_REASON_PLANNER_OUTPUT_INVALID" 26 "UI_ABORT_REASON_FOLLOWER_OUTPUT_INVALID" 25 "UI_ABORT_REASON_VEHICLE_SPEED_ABOVE_MAX" 24 "UI_ABORT_REASON_DRIVING_OFF_NAV" 23 "UI_ABORT_REASON_CID_SWITCH_DISABLED" 22 "UI_ABORT_REASON_CRUISE_FAULT" 21 "UI_ABORT_REASON_COMPONENT_MIA" 20 "UI_ABORT_REASON_EPAS_EAC_DENIED" 19 "UI_ABORT_REASON_SIDE_COLLISION_IMMINENT" 18 "UI_ABORT_REASON_TRAILER_MODE" 17 "UI_ABORT_REASON_CAM_WATCHDOG" 16 "UI_ABORT_REASON_CAM_MSG_MIA" 15 "UI_ABORT_REASON_ME_MAIN_STATE_NOT_VISION" 14 "UI_ABORT_REASON_APP_ME_STATE_NOT_VISION" 2 "UI_ABORT_REASON_HM_STEERING_ERROR" 1 "UI_ABORT_REASON_HM_VIRTUAL_LANE_NO_INPUTS" 0 "UI_ABORT_REASON_HM_LANE_VIEW_RANGE" ;
VAL_ 586 DAS_navAvailable 1 "DAS_NAV_AVAILABLE" 0 "DAS_NAV_UNAVAILABLE" ;
VAL_ 586 DAS_accSmartSpeedState 7 "SNA" 5 "OFFRAMP_DELAY" 4 "SET_SPEED_SET_REQUESTED" 3 "ACTIVE_ONRAMP" 2 "ACTIVE_INTEGRATING" 1 "ACTIVE_OFFRAMP" 0 "NOT_ACTIVE" ;
VAL_ 586 DAS_ulcInProgress 1 "ULC_ACTIVE" 0 "ULC_INACTIVE" ;
VAL_ 586 DAS_isaSystemState 3 "ISA_UNAVAILABLE" 2 "ISA_INVALID" 1 "ISA_ASSUMED_LIMITS" 0 "ISA_NOMINAL" ;
VAL_ 586 DAS_behaviorType 3 "DAS_BEHAVIOR_LANE_CHANGE_RIGHT" 2 "DAS_BEHAVIOR_LANE_CHANGE_LEFT" 1 "DAS_BEHAVIOR_IN_LANE" 0 "DAS_BEHAVIOR_INVALID" ;
VAL_ 586 DAS_ulcType 2 "ULC_TYPE_SPEED" 1 "ULC_TYPE_NAV" 0 "ULC_TYPE_NONE" ;
VAL_ 586 DAS_rearVehDetectedThisCycle 1 "VEHICLE_DETECTED" 0 "VEHICLE_NOT_DETECTED" ;
VAL_ 586 DAS_rearLeftVehDetectedCurrent 1 "VEHICLE_DETECTED" 0 "VEHICLE_NOT_DETECTED" ;
VAL_ 586 DAS_rearRightVehDetectedTrip 1 "VEHICLE_DETECTED" 0 "VEHICLE_NOT_DETECTED" ;
VAL_ 586 DAS_rearLeftVehDetectedTrip 1 "VEHICLE_DETECTED" 0 "VEHICLE_NOT_DETECTED" ;
VAL_ 977 EPAS3S_resyncStatus 1 "RESYNC_COMPLETE" 0 "RESYNC_PENDING" ;
VAL_ 785 EPAS3S_infoIndex 255 "END" 31 "SUBCOMPONENT_GITHASH" 30 "PACKAGE_SN_8_14" 29 "PACKAGE_SN_1_7" 27 "PACKAGE_PN_15_20" 26 "PACKAGE_PN_8_14" 25 "PACKAGE_PN_1_7" 23 "SUBCOMPONENT2" 22 "VARIANTCRC" 20 "UDS_PROTOCOL_BOOTCRC" 19 "VERSION_DEPRECATED" 18 "BOOTLOADER_GITHASH" 17 "APP_GITHASH" 16 "SUBCOMPONENT" 15 "BOOTLOADER_CRC" 14 "BOOTLOADER_SVN" 13 "APP_CRC" 11 "PCBAID_ASSYID_USAGEID" 10 "BUILD_HWID_COMPONENTID" 9 "DEPRECATED_9" 8 "DEPRECATED_8" 7 "DEPRECATED_7" 6 "DEPRECATED_6" 5 "DEPRECATED_5" 4 "DEPRECATED_4" 3 "DEPRECATED_3" 2 "DEPRECATED_2" 1 "DEPRECATED_1" 0 "DEPRECATED_0" ;
VAL_ 785 EPAS3S_infoBuildType 4 "INFO_MFG_BUILD" 3 "INFO_TRACEABLE_CI_BUILD" 2 "INFO_LOCAL_BUILD" 1 "INFO_PLATFORM_BUILD" 0 "INFO_UNKNOWN_BUILD" ;
VAL_ 805 ESP_infoIndex 255 "END" 31 "SUBCOMPONENT_GITHASH" 30 "PACKAGE_SN_8_14" 29 "PACKAGE_SN_1_7" 27 "PACKAGE_PN_15_20" 26 "PACKAGE_PN_8_14" 25 "PACKAGE_PN_1_7" 23 "SUBCOMPONENT2" 22 "VARIANTCRC" 20 "UDS_PROTOCOL_BOOTCRC" 19 "VERSION_DEPRECATED" 18 "BOOTLOADER_GITHASH" 17 "APP_GITHASH" 16 "SUBCOMPONENT" 15 "BOOTLOADER_CRC" 14 "BOOTLOADER_SVN" 13 "APP_CRC" 11 "PCBAID_ASSYID_USAGEID" 10 "BUILD_HWID_COMPONENTID" 9 "DEPRECATED_9" 8 "DEPRECATED_8" 7 "DEPRECATED_7" 6 "DEPRECATED_6" 5 "DEPRECATED_5" 4 "DEPRECATED_4" 3 "DEPRECATED_3" 2 "DEPRECATED_2" 1 "DEPRECATED_1" 0 "DEPRECATED_0" ;
VAL_ 805 ESP_infoBuildType 4 "INFO_MFG_BUILD" 3 "INFO_TRACEABLE_CI_BUILD" 2 "INFO_LOCAL_BUILD" 1 "INFO_PLATFORM_BUILD" 0 "INFO_UNKNOWN_BUILD" ;
VAL_ 805 ESP_infoSubUsageID 16 "XCP_Dfive_ESP_CP_CB" 8 "nonXCP_Dfour_ESP_CP_CB" 4 "XCP_Gladiator_ESP" 2 "nonXCP_Rev_C_ESP_Cappella" 0 "nonXCP_Rev_B_ESP_Cappella" ;
VAL_ 805 ESP_infoVehicleVariant 9 "MODEL_3_VARIANT_09" 8 "MODEL_3_VARIANT_08" 7 "MODEL_3_VARIANT_07" 6 "MODEL_3_VARIANT_06" 5 "MODEL_3_VARIANT_05" 4 "MODEL_3_VARIANT_04" 3 "MODEL_3_VARIANT_03" 2 "MODEL_3_VARIANT_02" 1 "MODEL_3_VARIANT_01" ;
VAL_ 813 IBST_infoIndex 255 "END" 31 "SUBCOMPONENT_GITHASH" 30 "PACKAGE_SN_8_14" 29 "PACKAGE_SN_1_7" 27 "PACKAGE_PN_15_20" 26 "PACKAGE_PN_8_14" 25 "PACKAGE_PN_1_7" 23 "SUBCOMPONENT2" 22 "VARIANTCRC" 20 "UDS_PROTOCOL_BOOTCRC" 19 "VERSION_DEPRECATED" 18 "BOOTLOADER_GITHASH" 17 "APP_GITHASH" 16 "SUBCOMPONENT" 15 "BOOTLOADER_CRC" 14 "BOOTLOADER_SVN" 13 "APP_CRC" 11 "PCBAID_ASSYID_USAGEID" 10 "BUILD_HWID_COMPONENTID" 9 "DEPRECATED_9" 8 "DEPRECATED_8" 7 "DEPRECATED_7" 6 "DEPRECATED_6" 5 "DEPRECATED_5" 4 "DEPRECATED_4" 3 "DEPRECATED_3" 2 "DEPRECATED_2" 1 "DEPRECATED_1" 0 "DEPRECATED_0" ;
VAL_ 813 IBST_infoBuildType 4 "INFO_MFG_BUILD" 3 "INFO_TRACEABLE_CI_BUILD" 2 "INFO_LOCAL_BUILD" 1 "INFO_PLATFORM_BUILD" 0 "INFO_UNKNOWN_BUILD" ;
VAL_ 806 PARK_infoIndex 255 "END" 31 "SUBCOMPONENT_GITHASH" 30 "PACKAGE_SN_8_14" 29 "PACKAGE_SN_1_7" 27 "PACKAGE_PN_15_20" 26 "PACKAGE_PN_8_14" 25 "PACKAGE_PN_1_7" 23 "SUBCOMPONENT2" 22 "VARIANTCRC" 20 "UDS_PROTOCOL_BOOTCRC" 19 "VERSION_DEPRECATED" 18 "BOOTLOADER_GITHASH" 17 "APP_GITHASH" 16 "SUBCOMPONENT" 15 "BOOTLOADER_CRC" 14 "BOOTLOADER_SVN" 13 "APP_CRC" 11 "PCBAID_ASSYID_USAGEID" 10 "BUILD_HWID_COMPONENTID" 9 "DEPRECATED_9" 8 "DEPRECATED_8" 7 "DEPRECATED_7" 6 "DEPRECATED_6" 5 "DEPRECATED_5" 4 "DEPRECATED_4" 3 "DEPRECATED_3" 2 "DEPRECATED_2" 1 "DEPRECATED_1" 0 "DEPRECATED_0" ;
VAL_ 806 PARK_infoBuildType 4 "INFO_MFG_BUILD" 3 "INFO_TRACEABLE_CI_BUILD" 2 "INFO_LOCAL_BUILD" 1 "INFO_PLATFORM_BUILD" 0 "INFO_UNKNOWN_BUILD" ;
VAL_ 846 PARK_frontLeftMiddleRawDistData 255 "SNA" ;
VAL_ 846 PARK_frontMiddleRawDistData 255 "SNA" ;
VAL_ 846 PARK_frontRightMiddleRawDistData 255 "SNA" ;
VAL_ 926 PARK_rightSideFrontRawDistData 255 "SNA" ;
VAL_ 926 PARK_rightSideRearRawDistData 255 "SNA" ;
VAL_ 926 PARK_leftSideFrontRawDistData 255 "SNA" ;
VAL_ 926 PARK_leftSideRearRawDistData 255 "SNA" ;
